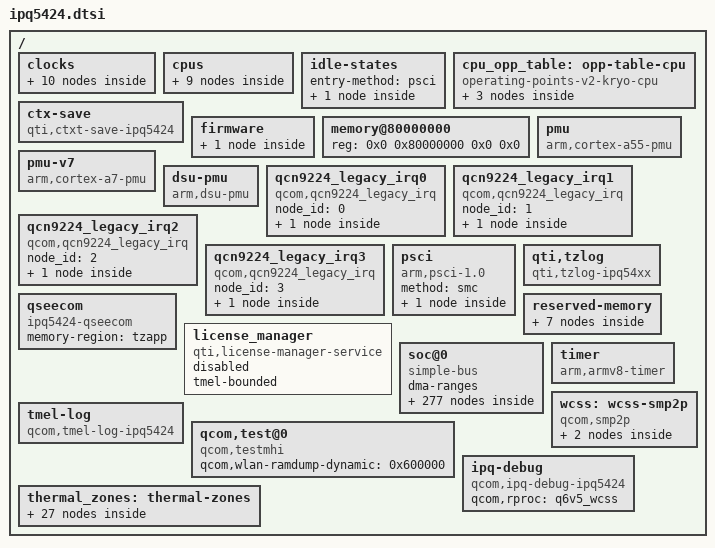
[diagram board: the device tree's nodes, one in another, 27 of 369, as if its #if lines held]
// SPDX-License-Identifier: (GPL-2.0+ OR BSD-3-Clause)
/*
 * IPQ5424 device tree source
 *
 * Copyright (c) 2020-2021 The Linux Foundation. All rights reserved.
 * Copyright (c) 2022-2024 Qualcomm Innovation Center, Inc. All rights reserved.
 */

#include <dt-bindings/interrupt-controller/arm-gic.h>
#include <dt-bindings/clock/qcom,apss-ipq.h>
#include <dt-bindings/clock/qcom,ipq5424-gcc.h>
#include <dt-bindings/reset/qcom,ipq5424-gcc.h>
#include <dt-bindings/gpio/gpio.h>
#include <dt-bindings/clock/qcom,ipq5424-nsscc.h>
#include <dt-bindings/reset/qcom,ipq5424-nsscc.h>

/ {
#ifdef __IPQ_MEM_PROFILE_256_MB__
	MP_256;
#elif __IPQ_MEM_PROFILE_512_MB__
	MP_512;
#endif
	#address-cells = <2>;
	#size-cells = <2>;
	interrupt-parent = <&intc>;

	clocks {
		pcie30_phy0_pipe_clk: pcie30_phy0_pipe_clk {
			compatible = "fixed-clock";
			clock-frequency = <250000000>;
			#clock-cells = <0>;
		};

		pcie30_phy1_pipe_clk: pcie30_phy1_pipe_clk {
			compatible = "fixed-clock";
			clock-frequency = <250000000>;
			#clock-cells = <0>;
		};

		pcie30_phy2_pipe_clk: pcie30_phy2_pipe_clk {
			compatible = "fixed-clock";
			clock-frequency = <250000000>;
			#clock-cells = <0>;
		};

		pcie30_phy3_pipe_clk: pcie30_phy3_pipe_clk {
			compatible = "fixed-clock";
			clock-frequency = <250000000>;
			#clock-cells = <0>;
		};

		sleep_clk: sleep-clk {
			compatible = "fixed-clock";
			#clock-cells = <0>;
		};

		usb_pcie_wrapper_pipe_clk: usb-pcie-wrapper-pipe-clk {
			compatible = "fixed-clock";
			clock-frequency = <125000000>;
			#clock-cells = <0>;
		};

		xo: xo {
			compatible = "fixed-clock";
			#clock-cells = <0>;
		};

		cmn_pll_nss_clk_375m: cmn-pll-nss-clk-375m {
			compatible = "fixed-clock";
			clock-frequency = <375000000>;
			#clock-cells = <0>;
		};

		cmn_pll_nss_clk_300m: cmn-pll-nss-clk-300m {
			compatible = "fixed-clock";
			clock-frequency = <300000000>;
			#clock-cells = <0>;
		};

		gcc_gpll0_out_aux: gcc-gpll0-out-aux {
			compatible = "fixed-clock";
			clock-frequency = <800000000>;
			#clock-cells = <0>;
		};
	};

	cpus: cpus {
		#address-cells = <1>;
		#size-cells = <0>;

		CPU0: cpu@0 {
			device_type = "cpu";
			compatible = "arm,cortex-a55";
			reg = <0x0>;
			enable-method = "psci";
			next-level-cache = <&L2_0>;
			cpu-idle-states = <&LITTLE_CPU_OFF>;
			clocks = <&apss_clk APSS_SILVER_CORE_CLK>;
			clock-names = "cpu";
			operating-points-v2 = <&cpu_opp_table>;
			#cooling-cells = <2>;
			L2_0: l2-cache {
				compatible = "cache";
				cache-level = <2>;
				cache-unified;
				next-level-cache = <&L3_0>;
				L3_0: l3-cache {
					compatible = "cache";
					cache-level = <3>;
					cache-unified;
				};
			};
		};

		CPU1: cpu@100 {
			device_type = "cpu";
			compatible = "arm,cortex-a55";
			enable-method = "psci";
			reg = <0x100>;
			next-level-cache = <&L2_100>;
			cpu-idle-states = <&LITTLE_CPU_OFF>;
			clocks = <&apss_clk APSS_SILVER_CORE_CLK>;
			clock-names = "cpu";
			operating-points-v2 = <&cpu_opp_table>;
			#cooling-cells = <2>;
			L2_100: l2-cache {
				compatible = "cache";
				cache-level = <2>;
				cache-unified;
				next-level-cache = <&L3_0>;
			};
		};

		CPU2: cpu@200 {
			device_type = "cpu";
			compatible = "arm,cortex-a55";
			enable-method = "psci";
			reg = <0x200>;
			next-level-cache = <&L2_200>;
			cpu-idle-states = <&LITTLE_CPU_OFF>;
			clocks = <&apss_clk APSS_SILVER_CORE_CLK>;
			clock-names = "cpu";
			operating-points-v2 = <&cpu_opp_table>;
			#cooling-cells = <2>;
			L2_200: l2-cache {
				compatible = "cache";
				cache-level = <2>;
				cache-unified;
				next-level-cache = <&L3_0>;
			};
		};

		CPU3: cpu@300 {
			device_type = "cpu";
			compatible = "arm,cortex-a55";
			enable-method = "psci";
			reg = <0x300>;
			next-level-cache = <&L2_300>;
			cpu-idle-states = <&LITTLE_CPU_OFF>;
			clocks = <&apss_clk APSS_SILVER_CORE_CLK>;
			clock-names = "cpu";
			operating-points-v2 = <&cpu_opp_table>;
			#cooling-cells = <2>;
			L2_300: l2-cache {
				compatible = "cache";
				cache-level = <2>;
				cache-unified;
				next-level-cache = <&L3_0>;
			};
		};
	};

	idle-states {
		entry-method = "psci";

		LITTLE_CPU_OFF: silver-c3 {  /* C3 */
			compatible = "arm,idle-state";
			idle-state-name = "pc";
			entry-latency-us = <549>;
			exit-latency-us = <901>;
			min-residency-us = <1774>;
			arm,psci-suspend-param = <0x40000003>;
			local-timer-stop;
		};
	};

	cpu_opp_table: opp-table-cpu {
		compatible = "operating-points-v2-kryo-cpu";
		opp-shared;
		nvmem-cells = <&apss_cpu_freq>;
		nvmem-cell-names = "cpu_freq";

		/* Listed all supported CPU frequencies and opp-supported-hw
		 * values to select CPU frequencies based on the PLL LValue.
		 * ------------------------------------------------------------
		 * Frequency     1.4GHz	   1.8GHz(no limit)	opp-supported-hw
		 * ------------------------------------------------------------
		 * 816000000	   1	      1			0x3
		 * 1416000000      1	      1			0x3
		 * 1800000000      0	      1			0x1
		 * -----------------------------------------------------------*/

		opp-816000000 {
			opp-hz = /bits/ 64 <816000000>;
			opp-supported-hw = <0x3>;
			opp-microvolt = <850000>;
			clock-latency-ns = <200000>;
		};

		opp-1416000000 {
			opp-hz = /bits/ 64 <1416000000>;
			opp-supported-hw = <0x3>;
			opp-microvolt = <850000>;
			clock-latency-ns = <200000>;
		};

		opp-1800000000 {
			opp-hz = /bits/ 64 <1800000000>;
			opp-supported-hw = <0x1>;
			opp-microvolt = <1000000>;
			clock-latency-ns = <200000>;
		};
	};

	ctx-save {
		compatible = "qti,ctxt-save-ipq5424";
		memory-region = <&minidump_mem>;
		qcom,imem = <&imem>;
		minidump-level = <2>;
	};

	firmware {
		scm {
			compatible = "qcom,scm-ipq5424", "qcom,scm";
			qcom,dload-mode = <&tcsr 0x25100>;
			qcom,tcsr-boot-info = <&tcsr 0x25158>;
		};
	};

	memory@80000000 {
		device_type = "memory";
		/* We expect the bootloader to fill in the size */
		reg = <0x0 0x80000000 0x0 0x0>;
	};

	pmu {
		compatible = "arm,cortex-a55-pmu";
		interrupts = <GIC_PPI 7 (GIC_CPU_MASK_SIMPLE(4) | IRQ_TYPE_LEVEL_HIGH)>;
	};

	pmu-v7 {
		compatible = "arm,cortex-a7-pmu";
		interrupts = <GIC_PPI 7 (GIC_CPU_MASK_SIMPLE(4) | IRQ_TYPE_LEVEL_HIGH)>;
	};

	dsu-pmu {
                compatible = "arm,dsu-pmu";
                interrupts = <GIC_SPI 50 IRQ_TYPE_EDGE_RISING 0>;
                cpus = <&CPU0>, <&CPU1>, <&CPU2>, <&CPU3>;
                status = "ok";
        };

        qcn9224_legacy_irq0: qcn9224_legacy_irq0 {
		compatible = "qcom,qcn9224_legacy_irq";
		node_id = <0>;
		status = "okay";

		qcn9224_in0: legacy_interrupt {
			interrupt-controller;
			#interrupt-cells = <2>;
		};
	};

	qcn9224_legacy_irq1: qcn9224_legacy_irq1 {
		compatible = "qcom,qcn9224_legacy_irq";
		node_id = <1>;
		status = "okay";

		qcn9224_in1: legacy_interrupt {
			interrupt-controller;
			#interrupt-cells = <2>;
		};
	};

	qcn9224_legacy_irq2: qcn9224_legacy_irq2 {
		compatible = "qcom,qcn9224_legacy_irq";
		node_id = <2>;
		status = "okay";

		qcn9224_in2: legacy_interrupt {
			interrupt-controller;
			#interrupt-cells = <2>;
		};
	};

	qcn9224_legacy_irq3: qcn9224_legacy_irq3 {
		compatible = "qcom,qcn9224_legacy_irq";
		node_id = <3>;
		status = "okay";

		qcn9224_in3: legacy_interrupt {
			interrupt-controller;
			#interrupt-cells = <2>;
		};
	};

	psci {
		compatible = "arm,psci-1.0";
		method = "smc";
		reset-types {
			mode-edl = <0 0x1>;
		};
	};

	qti,tzlog {
		compatible = "qti,tzlog-ipq54xx";
		interrupts = <GIC_SPI 56 IRQ_TYPE_EDGE_RISING>;
		qti,tz-diag-buf-size = <0x3000>;
		qti,tz-ring-off = <7>;
		qti,tz-log-pos-info-off = <822>;
	};

	qseecom: qseecom {
		compatible = "ipq5424-qseecom";
#if !defined(__IPQ_MEM_PROFILE_256_MB__)
		memory-region = <&tzapp>;
#endif
	};

	reserved-memory {
		#address-cells = <2>;
		#size-cells = <2>;
		ranges;

#if !defined(__IPQ_MEM_PROFILE_256_MB__)
		tzapp: tzapp@0x89900000 {
		#if !defined(__IPQ_MEM_PROFILE_512_MB__)
			reg = <0x0 0x89900000 0x0 0x600000>;
		#endif
			no-map;
		};

		bootloader@0x8a200000 {
			reg = <0x0 0x8a200000 0x0 0x400000>;
			no-map;
		};

#else
		secure_upgrade: secure_upgrade@0 {
			reg = <0x0 0x8a300000 0x0 0x500000>;
			no-map;
			status = "disabled";
		};
#endif
		tz@0x8a600000 {
			reg = <0x0 0x8a600000 0x0 0x200000>;
			no-map;
#if defined(__IPQ_MEM_PROFILE_256_MB__)
			status = "disabled";
#endif
		};

		smem@8a800000 {
			compatible = "qcom,smem";
			reg = <0x0 0x8a800000 0x0 0x32000>;
			no-map;

			hwlocks = <&tcsr_mutex 3>;
		};

		atf@8a832000 {
			reg = <0x0 0x8a832000 0x0 0x80000>;
			no-map;
			status = "disabled";
		};

		tmc_etr_region: tmc_etr_dump@0 {
			no-map;
			status = "disabled";
		};

		minidump_mem: minidump_mem@0 {
			no-map;
		};
	};

	license_manager: license_manager {
		compatible = "qti,license-manager-service";
		tmel-bounded;
		status = "disabled";
	};

	soc@0 {
		compatible = "simple-bus";
		#address-cells = <1>;
		#size-cells = <1>;
		ranges = <0 0 0 0xffffffff>;
		dma-ranges;

		qfprom {
			compatible = "qcom,qfprom-ipq5424-sec";
			scm-cmd-id = <0x1f>;
			version-commit-enable = <0x1>;
			reg = <0xA0058 0x4>;
		};

		tsens: thermal-sensor@4a9000 {
			compatible = "qcom,ipq5424-tsens";
			reg = <0x4a9000 0x1000>,
			      <0x4a8000 0x1000>;
			nvmem-cells = <&tsens_mode>, <&tsens_base0>, <&tsens_base1>,
				      <&s9>, <&s10>, <&s11>, <&s12>, <&s13>, <&s14>,
				      <&s15>;
			nvmem-cell-names = "mode", "base0", "base1", "s9",
					   "s10", "s11", "s12", "s13",
					   "s14", "s15";
			interrupts = <GIC_SPI 105 IRQ_TYPE_EDGE_RISING>;
			interrupt-names = "combined";
			#thermal-sensor-cells = <1>;
		};

		eud {
			compatible = "qcom,sc7280-eud","qcom,eud";
			reg = <0x78000 0x2000>,
			      <0x7A000 0x1000>;
			interrupts = <GIC_SPI 415 IRQ_TYPE_LEVEL_HIGH>;
			clocks = <&gcc GCC_USB0_PHY_CFG_AHB_CLK>;
			clock-names = "eud_ahb2phy_clk";
			status = "disabled";
		};

		rng: rng@4c3000 {
			compatible = "qcom,trng";
			reg = <0x004c3000 0x1000>;
			clocks = <&gcc GCC_PRNG_AHB_CLK>;
			clock-names = "core";
		};

		system-cache-controller@800000 {
			compatible = "qcom,ipq5424-llcc";
			reg = <0x00800000 0x200000>, <0x00800000 0x200000>;
			reg-names = "llcc_base", "llcc_broadcast_base";
			interrupts = <GIC_SPI 68 IRQ_TYPE_LEVEL_HIGH>;
			status = "disabled";

			llcc-perfmon {
				compatible = "qcom,llcc-perfmon";
			};
		};

		tlmm: pinctrl@1000000 {
			compatible = "qcom,ipq5424-tlmm";
			reg = <0x01000000 0x300000>;
			interrupts = <GIC_SPI 84 IRQ_TYPE_LEVEL_HIGH>;
			gpio-controller;
			#gpio-cells = <2>;
			gpio-ranges = <&tlmm 0 0 50>;
			interrupt-controller;
			#interrupt-cells = <2>;

			qup_uart0_default: qup-uart0-default-state {
				qup_uart0_tx: tx-pins {
					pins = "gpio13";
					function = "uart0_tx";
					drive-strength = <8>;
					bias-pull-down;
				};

				qup_uart0_rx: rx-pins {
					pins = "gpio12";
					function = "uart0_rx";
					drive-strength = <8>;
					bias-pull-down;
				};

				qup_uart0_rfr: rfr-pins {
					pins = "gpio10";
					function = "uart0_rfr";
					drive-strength = <8>;
					bias-pull-down;
				};

				qup_uart0_cts: cts-pins {
					pins = "gpio11";
					function = "uart0_cts";
					drive-strength = <8>;
					bias-pull-down;
				};
			};
		};

		pcie0_phy: phy@84000 {
			compatible = "qcom,ipq5424-qmp-gen3x1-pcie-phy",
				     "qcom,ipq9574-qmp-gen3x1-pcie-phy";
			reg = <0x00084000 0x1bc>; /* Serdes PLL */
			#address-cells = <1>;
			#size-cells = <1>;
			ranges;

			clocks = <&gcc GCC_PCIE0_AUX_CLK>,
				 <&gcc GCC_PCIE0_AHB_CLK>,
				 <&gcc GCC_ANOC_PCIE0_1LANE_M_CLK>,
				 <&gcc GCC_CNOC_PCIE0_1LANE_S_CLK>;
			clock-names = "aux", "cfg_ahb", "anoc_lane", "snoc_lane";

			assigned-clocks = <&gcc GCC_PCIE0_AUX_CLK>,
					  <&gcc GCC_PCIE0_AHB_CLK>,
					  <&gcc GCC_ANOC_PCIE0_1LANE_M_CLK>,
					  <&gcc GCC_CNOC_PCIE0_1LANE_S_CLK>;
			assigned-clock-rates = <20000000>,
					       <100000000>,
					       <240000000>,
					       <240000000>;

			resets = <&gcc GCC_PCIE0_PHY_BCR>,
				 <&gcc GCC_PCIE0PHY_PHY_BCR>;
			reset-names = "phy", "common";

			status = "disabled";

			pcie0_lanes: phy@84200 {
				reg = <0x00084200 0x16c>, /* Serdes Tx0 */
				      <0x00084400 0x200>, /* Serdes Rx0 */
				      <0x00084800 0x1f0>, /* PCS: Lane0, COM, PCIE */
				      <0x00084c00 0x0f4>; /* pcs_misc */

				#phy-cells = <0>;

				clocks = <&gcc GCC_PCIE0_PIPE_CLK>;
				clock-names = "pipe0";
				clock-output-names = "gcc_pcie0_pipe_clk_src";
				#clock-cells = <0>;
			};
		};

		pcie1_phy: phy@8c000 {
			compatible = "qcom,ipq5424-qmp-gen3x1-pcie-phy",
				     "qcom,ipq9574-qmp-gen3x1-pcie-phy";
			reg = <0x0008c000 0x1bc>; /* Serdes PLL */
			#address-cells = <1>;
			#size-cells = <1>;
			ranges;

			clocks = <&gcc GCC_PCIE1_AUX_CLK>,
				 <&gcc GCC_PCIE1_AHB_CLK>,
				 <&gcc GCC_ANOC_PCIE1_1LANE_M_CLK>,
				 <&gcc GCC_CNOC_PCIE1_1LANE_S_CLK>;
			clock-names = "aux", "cfg_ahb", "anoc_lane", "snoc_lane";

			assigned-clocks = <&gcc GCC_PCIE1_AUX_CLK>,
					  <&gcc GCC_PCIE1_AHB_CLK>,
					  <&gcc GCC_ANOC_PCIE1_1LANE_M_CLK>,
					  <&gcc GCC_CNOC_PCIE1_1LANE_S_CLK>;
			assigned-clock-rates = <20000000>,
					       <100000000>,
					       <240000000>,
					       <240000000>;

			resets = <&gcc GCC_PCIE1_PHY_BCR>,
				 <&gcc GCC_PCIE1PHY_PHY_BCR>;
			reset-names = "phy", "common";

			status = "disabled";

			pcie1_lanes: phy@8c200 {
				reg = <0x0008c200 0x16c>, /* Serdes Tx0 */
				      <0x0008c400 0x200>, /* Serdes Rx0 */
				      <0x0008c800 0x1f0>, /* PCS: Lane0, COM, PCIE */
				      <0x0008cc00 0x0f4>; /* pcs_misc */

				#phy-cells = <0>;

				clocks = <&gcc GCC_PCIE1_PIPE_CLK>;
				clock-names = "pipe0";
				clock-output-names = "gcc_pcie1_pipe_clk_src";
				#clock-cells = <0>;
			};
		};

		pcie2_phy: phy@f4000 {
			compatible = "qcom,ipq5424-qmp-gen3x2-pcie-phy",
				     "qcom,ipq9574-qmp-gen3x2-pcie-phy";
			reg = <0x000f4000 0x1bc>; /* Serdes PLL */
			#address-cells = <1>;
			#size-cells = <1>;
			ranges;

			clocks = <&gcc GCC_PCIE2_AUX_CLK>,
				 <&gcc GCC_PCIE2_AHB_CLK>,
				 <&gcc GCC_ANOC_PCIE2_2LANE_M_CLK>,
				 <&gcc GCC_CNOC_PCIE2_2LANE_S_CLK>;
			clock-names = "aux", "cfg_ahb", "anoc_lane", "snoc_lane";

			assigned-clocks = <&gcc GCC_PCIE2_AUX_CLK>,
					  <&gcc GCC_PCIE2_AHB_CLK>,
					  <&gcc GCC_ANOC_PCIE2_2LANE_M_CLK>,
					  <&gcc GCC_CNOC_PCIE2_2LANE_S_CLK>;
			assigned-clock-rates = <20000000>,
					       <100000000>,
					       <266666666>,
					       <240000000>;

			resets = <&gcc GCC_PCIE2_PHY_BCR>,
				 <&gcc GCC_PCIE2PHY_PHY_BCR>;
			reset-names = "phy", "common";

			status = "disabled";

			pcie2_lanes: phy@f4200 {
				reg = <0x000f4200 0x16c>, /* Serdes Tx0 */
				      <0x000f4400 0x200>, /* Serdes Rx0 */
				      <0x000f5000 0x1f0>, /* PCS: Lane0, COM, PCIE */
				      <0x000f4600 0x16c>, /* Serdes Tx1 */
				      <0x000f4800 0x200>, /* Serdes Rx1 */
				      <0x000f5400 0x0f8>; /* pcs_misc */

				#phy-cells = <0>;

				clocks = <&gcc GCC_PCIE2_PIPE_CLK>;
				clock-names = "pipe0";
				clock-output-names = "gcc_pcie2_pipe_clk_src";
				#clock-cells = <0>;
			};
		};

		pcie3_phy: phy@fc000 {
			compatible = "qcom,ipq5424-qmp-gen3x2-pcie-phy",
				     "qcom,ipq9574-qmp-gen3x2-pcie-phy";
			reg = <0x000fc000 0x1bc>; /* Serdes PLL */
			#address-cells = <1>;
			#size-cells = <1>;
			ranges;

			clocks = <&gcc GCC_PCIE3_AUX_CLK>,
				 <&gcc GCC_PCIE3_AHB_CLK>,
				 <&gcc GCC_ANOC_PCIE3_2LANE_M_CLK>,
				 <&gcc GCC_CNOC_PCIE3_2LANE_S_CLK>;
			clock-names = "aux", "cfg_ahb", "anoc_lane", "snoc_lane";

			assigned-clocks = <&gcc GCC_PCIE3_AUX_CLK>,
					  <&gcc GCC_PCIE3_AHB_CLK>,
					  <&gcc GCC_ANOC_PCIE3_2LANE_M_CLK>,
					  <&gcc GCC_CNOC_PCIE3_2LANE_S_CLK>;
			assigned-clock-rates = <20000000>,
					       <100000000>,
					       <266666666>,
					       <240000000>;

			resets = <&gcc GCC_PCIE3_PHY_BCR>,
				 <&gcc GCC_PCIE3PHY_PHY_BCR>;
			reset-names = "phy", "common";

			status = "disabled";

			pcie3_lanes: phy@fc200 {
				reg = <0x000fc200 0x16c>, /* Serdes Tx0 */
				      <0x000fc400 0x200>, /* Serdes Rx0 */
				      <0x000fd000 0x1f0>, /* PCS: Lane0, COM, PCIE */
				      <0x000fc600 0x16c>, /* Serdes Tx1 */
				      <0x000fc800 0x200>, /* Serdes Rx1 */
				      <0x000fd400 0x0f8>; /* pcs_misc */

				#phy-cells = <0>;

				clocks = <&gcc GCC_PCIE3_PIPE_CLK>;
				clock-names = "pipe0";
				clock-output-names = "gcc_pcie3_pipe_clk_src";
				#clock-cells = <0>;
			};
		};

		efuse@a4000 {
			compatible = "qcom,qfprom";
			reg = <0xA4000 0x741>;
			#address-cells = <1>;
			#size-cells = <1>;

			s9: s9@3dc {
				reg = <0x3dc 0x1>;
				bits = <4 4>;
			};

			s10: s10@3dd {
				reg = <0x3dd 0x1>;
				bits = <0 4>;
			};

			s11: s11@3dd {
				reg = <0x3dd 0x1>;
				bits = <4 4>;
			};

			s12: s12@3de {
				reg = <0x3de 0x1>;
				bits = <0 4>;
			};

			s13: s13@3de {
				reg = <0x3de 0x1>;
				bits = <4 4>;
			};

			s14: s14@3e5 {
				reg = <0x3e5 0x2>;
				bits = <7 4>;
			};

			s15: s15@3e6 {
				reg = <0x3e6 0x1>;
				bits = <3 4>;
			};

			tsens_mode: mode@419 {
				reg = <0x419 0x1>;
				bits = <0 3>;
			};

			tsens_base0: base0@419 {
				reg = <0x419 0x2>;
				bits = <3 10>;
			};

			tsens_base1: base1@41a {
				reg = <0x41a 0x2>;
				bits = <5 10>;
			};
		};

		softsku@a6000 {
			compatible = "qcom,qfprom";
			reg = <0xA6000 0x1000>;
			#address-cells = <1>;
			#size-cells = <1>;

			apss_cpu_freq: apss_cpu_freq@234 {
				reg = <0x234 0x1>;
				bits = <0 8>;
			};

			ddr_space_limit: ddr_space_limit@23c {
				reg = <0x23c 0x1>;
				bits = <0 1>;
			};

			pcie0_disable: pcie0_disable@244 {
				reg = <0x244 0x1>;
				bits = <0 1>;
			};

			pcie1_disable: pcie1_disable@24c {
				reg = <0x24c 0x1>;
				bits = <0 1>;
			};

			pcie2_disable: pcie2_disable@254 {
				reg = <0x254 0x1>;
				bits = <0 1>;
			};

			pcie3_disable: pcie3_disable@25c {
				reg = <0x25c 0x1>;
				bits = <0 1>;
			};

			uniphy0_disable: uniphy0_disable@264 {
				reg = <0x264 0x1>;
				bits = <0 1>;
			};

			uniphy1_disable: uniphy1_disable@26c {
				reg = <0x26c 0x1>;
				bits = <0 1>;
			};

			uniphy2_disable: uniphy2_disable@274 {
				reg = <0x274 0x1>;
				bits = <0 1>;
			};

			audio_disable: audio_disable@27c {
				reg = <0x27c 0x1>;
				bits = <0 1>;
			};

			nss_disable: nss_disable@284 {
				reg = <0x284 0x1>;
				bits = <0 1>;
			};

			usb_disable: usb_disable@28c {
				reg = <0x28c 0x1>;
				bits = <0 1>;
			};
		};

		gcc: clock-controller@1800000 {
			compatible = "qcom,ipq5424-gcc";
			reg = <0x01800000 0x40000>;
			clocks = <&xo>,
				 <&sleep_clk>,
				 <&pcie30_phy0_pipe_clk>,
				 <&pcie30_phy1_pipe_clk>,
				 <&pcie30_phy2_pipe_clk>,
				 <&pcie30_phy3_pipe_clk>,
				 <&usb_pcie_wrapper_pipe_clk>,
				 <&cmn_pll_nss_clk_375m>;
			#clock-cells = <1>;
			#reset-cells = <1>;
			#power-domain-cells = <1>;
                };

		nsscc: nsscc@39b00000{
			compatible = "qcom,ipq54xx-nsscc";
			reg = <0x39b00000 0x80000>;
			clocks = <&xo>,
				<&cmn_pll_nss_clk_375m>,
				<&cmn_pll_nss_clk_300m>,
				<&gcc_gpll0_out_aux>;
			clock-names = "xo",
					"cmn_pll_nss_clk_375m",
					"cmn_pll_nss_clk_300m",
					"gcc_gpll0_out_aux";
			#clock-cells = <0x1>;
			#reset-cells = <0x1>;
		};

		tcsr_mutex: hwlock@1905000 {
			compatible = "qcom,tcsr-mutex";
			reg = <0x1905000 0x20000>;
			#hwlock-cells = <1>;
		};

		tcsr: syscon@1937000 {
			compatible = "qcom,tcsr-ipq5424", "syscon", "simple-mfd";
			reg = <0x01937000 0x2a000>;
			#address-cells = <1>;
			#size-cells = <1>;
			ranges = <0x0 0x01937000 0x2a000>;

			 pwm: pwm@a010 {
				compatible = "qcom,ipq9574-pwm";
				reg = <0xa010 0x20>;
				clocks = <&gcc GCC_ADSS_PWM_CLK>;
				assigned-clocks = <&gcc GCC_ADSS_PWM_CLK>;
				assigned-clock-rates = <100000000>;
				#pwm-cells = <2>;
				status = "disabled";
			};
		};

		qupv3: geniqup@1ac0000 {
			compatible = "qcom,geni-se-qup";
			reg = <0x01ac0000 0x2000>;
			clocks = <&gcc GCC_QUPV3_AHB_MST_CLK>,
				 <&gcc GCC_QUPV3_AHB_SLV_CLK>;
			clock-names = "m-ahb", "s-ahb";
			ranges;
			#address-cells = <1>;
			#size-cells = <1>;

			status = "disabled";

			uart0: serial@1a80000 {
				compatible = "qcom,geni-uart";
				reg = <0x01a80000 0x4000>;
				clocks = <&gcc GCC_QUPV3_UART0_CLK>;
				clock-names = "se";
				interrupts = <GIC_SPI 339 IRQ_TYPE_LEVEL_HIGH>;
				status = "disabled";
			};

			uart1: serial@1a84000 {
				compatible = "qcom,geni-debug-uart";
				reg = <0x01a84000 0x4000>;
				clocks = <&gcc GCC_QUPV3_UART1_CLK>;
				clock-names = "se";
				interrupts = <GIC_SPI 340 IRQ_TYPE_LEVEL_HIGH>;
				status = "disabled";
			};

			i2c0: i2c@1a88000 {
				compatible = "qcom,geni-i2c";
				reg = <0x1a88000 0x4000>;
				clocks = <&gcc GCC_QUPV3_I2C0_CLK>;
				clock-names = "se";
				clock-frequency = <400000>;
				interrupts = <GIC_SPI 341 IRQ_TYPE_LEVEL_HIGH>;
				assigned-clocks = <&gcc GCC_QUPV3_I2C0_CLK>;
				assigned-clock-rates = <64000000>;
				status = "disabled";
			};

			i2c1: i2c@1a8c000 {
				compatible = "qcom,geni-i2c";
				reg = <0x1a8c000 0x4000>;
				clocks = <&gcc GCC_QUPV3_I2C1_CLK>;
				clock-names = "se";
				clock-frequency = <400000>;
				interrupts = <GIC_SPI 342 IRQ_TYPE_LEVEL_HIGH>;
				assigned-clocks = <&gcc GCC_QUPV3_I2C1_CLK>;
				assigned-clock-rates = <64000000>;
				status = "disabled";
			};

			spi0: spi@1a90000 {
				compatible = "qcom,geni-spi";
				reg = <0x1a90000 0x4000>;
				clocks = <&gcc GCC_QUPV3_SPI0_CLK>;
				clock-names = "se";
				interrupts = <GIC_SPI 343 IRQ_TYPE_LEVEL_HIGH>;
				assigned-clocks = <&gcc GCC_QUPV3_SPI0_CLK>;
				assigned-clock-rates = <50000000>;
				status = "disabled";
			};

			spi1: spi@1a94000 {
				compatible = "qcom,geni-spi";
				reg = <0x1a94000 0x4000>;
				clocks = <&gcc GCC_QUPV3_SPI1_CLK>;
				clock-names = "se";
				interrupts = <GIC_SPI 344 IRQ_TYPE_LEVEL_HIGH>;
				assigned-clocks = <&gcc GCC_QUPV3_SPI1_CLK>;
				assigned-clock-rates = <50000000>;
				status = "disabled";
			};
		};

		apss_clk: apss-clock@fa80000 {
			compatible = "qcom,apss-ipq5424-clk";
			reg = <0x0fa80000 0x20000>;
			clocks = <&xo>, <&gcc GPLL0>;
			clock-names = "xo", "gpll0";
			#clock-cells = <1>;
                };

		lpass: lpass@0xA000000{
			compatible = "qca,lpass-ipq5424";
			reg =  <0xA000000 0x3BFFFF>;
			clocks = <&gcc GCC_LPASS_SWAY_CLK>,
			<&gcc GCC_LPASS_CORE_AXIM_CLK>,
			<&gcc GCC_SNOC_LPASS_CLK>,
			<&gcc GCC_CNOC_LPASS_CFG_CLK>;
			clock-names = "sway", "axim", "snoc_cfg", "pcnoc";
			resets = <&gcc GCC_LPASS_BCR>;
			reset-names = "lpass";
			nvmem-cells = <&audio_disable>;
			#address-cells = <1>;
			#size-cells = <1>;
			ranges;
			status = "disabled";

			pcm: pcm@0xA3C0000{
				compatible = "qca,ipq5424-lpass-pcm";
				reg =  <0xA3C0000 0x23014>;
				status = "disabled";

				pcm0: pcm0@0 {
					interrupts = <0 159 IRQ_TYPE_LEVEL_HIGH>;
					interrupt-names = "out0";
					capture_memory = "lpm";
					playback_memory = "lpm";
					voice_loopback = <0>;
					slave = <0>;
					status = "disabled";
				};

				pcm1: pcm1@1 {
					interrupts = <0 160 IRQ_TYPE_LEVEL_HIGH>;
					interrupt-names = "out1";
					capture_memory = "lpm";
					playback_memory = "lpm";
					voice_loopback = <0>;
					slave = <0>;
					status = "disabled";
				};
			};
		};

		pcm_lb: pcm_lb@0 {
			compatible = "qca,ipq5424-pcm-lb";
			status = "disabled";
		};

		q6v5_wcss: remoteproc@d100000 {
			compatible = "qcom,ipq5424-q6v5-wcss-sec";
			#address-cells = <1>;
			#size-cells = <1>;
			ranges;
#ifdef __QCOM_NON_SECURE_PIL__
			reg = <0xd100000 0x4040>;
			reg-names = "qdsp6";
			resets = <&gcc GCC_WCSS_Q6_BCR>,
				 <&gcc GCC_WAPSS_BCR>;
			reset-names = "wcss_q6_reset",
				      "wapss_reset";
			clocks = <&gcc GCC_Q6_TSCTR_1TO2_CLK>,
				 <&gcc GCC_Q6SS_TRIG_CLK>,
				 <&gcc GCC_Q6_AHB_S_CLK>,
				 <&gcc GCC_Q6_AHB_CLK>,
				 <&gcc GCC_Q6SS_ATBM_CLK>,
				 <&gcc GCC_Q6_AXIM_CLK>,
				 <&gcc GCC_Q6SS_BOOT_CLK>,
				 <&gcc GCC_Q6SS_PCLKDBG_CLK>,
				 <&gcc GCC_WCSS_ECAHB_CLK>,
				 <&gcc GCC_CNOC_WCSS_AHB_CLK>;

			clock-names = "q6_tsctr_1to2",
				      "q6ss_trig",
				      "q6_ahb_s",
				      "q6_ahb",
				      "q6ss_atbm",
				      "q6_axim",
				      "q6ss_boot",
				      "q6ss_pclkdbg",
				      "wcss_ecahb",
				      "cnoc_wcss_ahb";
			qcom,q6-tcsr-regs = <&tcsr 0x26000 0x1B000>;
#endif
			firmware = "IPQ5424/q6_fw0.mdt";
			interrupts-extended = <&intc GIC_SPI 508 IRQ_TYPE_EDGE_RISING>,
					      <&wcss_smp2p_in 0 0>,
					      <&wcss_smp2p_in 1 0>,
					      <&wcss_smp2p_in 2 0>,
					      <&wcss_smp2p_in 3 0>;
			interrupt-names = "wdog",
					  "fatal",
					  "ready",
					  "handover",
					  "stop-ack";
			qcom,smem-states = <&wcss_smp2p_out 0>,
					   <&wcss_smp2p_out 1>;
			qcom,smem-state-names = "shutdown",
						"stop";

			memory-region = <&q6_region>,
					<&m3_dump>,
					<&q6_etr_region>,
					<&q6_ipq5424_caldb>,
					<&mlo_global_mem0>;
			qcom,bootargs_smem = <507>;
			qcom,bootargs_version = <2>;
			qcom,userpd-bootargs;
			upd-firmware-names = "IPQ5424/q6_fw1.mdt";
			status = "disabled";

			glink-edge {
				interrupts = <GIC_SPI 500 IRQ_TYPE_EDGE_RISING>;
				label = "rtr";
				qcom,remote-pid = <1>;
				mboxes = <&apcs_glb 8>;
				global_timer = <0x4A5000>;
			};

#ifdef __QCOM_NON_SECURE_PIL__
			q6_wcss_pd1: remoteproc_pd1 {
				compatible = "qcom,ipq5424-wcss-ahb-mpd";
				firmware = "IPQ5424/q6_fw1.mdt";
				m3_firmware = "IPQ5424/iu_fw.mdt";
				interrupts-extended = <&wcss_smp2p_in 8 0>,
						      <&wcss_smp2p_in 9 0>,
						      <&wcss_smp2p_in 12 0>,
						      <&wcss_smp2p_in 11 0>;
				interrupt-names = "fatal",
						  "ready",
						  "spawn-ack",
						  "stop-ack";

				qcom,smem-states = <&wcss_smp2p_out 8>,
						   <&wcss_smp2p_out 9>,
						   <&wcss_smp2p_out 10>;
				qcom,smem-state-names = "shutdown",
							"stop",
							"spawn";
				status = "disabled";
			};
#endif
		};

		userpd_1: userpd1 {
			compatible = "qcom,ipq5424-q6v5-upd";
			memory-region = <&q6_region>;
			qcom,rproc = <&q6v5_wcss>;
			firmware = "IPQ5424/q6_fw1.mdt";
			m3_firmware = "IPQ5424/iu_fw.mdt";
			interrupts-extended = <&wcss_smp2p_in 8 0>,
					      <&wcss_smp2p_in 9 0>,
					      <&wcss_smp2p_in 12 0>,
					      <&wcss_smp2p_in 11 0>;
			interrupt-names = "fatal",
					  "ready",
					  "spawn-ack",
					  "stop-ack";

			qcom,smem-states = <&wcss_smp2p_out 8>,
					   <&wcss_smp2p_out 9>,
					   <&wcss_smp2p_out 10>;
			qcom,smem-state-names = "shutdown",
						"stop",
						"spawn";
			status = "disabled";
		};

		intc: interrupt-controller@f200000 {
			compatible = "arm,gic-v3";
			reg = <0xf200000 0x10000>, /* GICD */
			      <0xf240000 0x80000>; /* GICR * 4 regions */
			#interrupt-cells = <0x3>;
			interrupt-controller;
			#redistributor-regions = <1>;
			redistributor-stride = <0x0 0x20000>;
			interrupts = <GIC_PPI 9 IRQ_TYPE_LEVEL_HIGH>;
			mbi-ranges = <672 128>;
			msi-controller;
		};

		mdio@90000 {
			compatible = "qcom,qca-mdio", "qcom,ipq40xx-mdio";
			reg = <0x90000 0x64>, <0x9B000 0x800>;
			reg-names = "ppe", "cmn_blk";
			#address-cells = <1>;
			#size-cells = <1>;
			clocks = <&gcc GCC_MDIO_AHB_CLK>,
				<&gcc GCC_UNIPHY0_AHB_CLK>,
				<&gcc GCC_UNIPHY0_SYS_CLK>,
				<&gcc GCC_UNIPHY1_AHB_CLK>,
				<&gcc GCC_UNIPHY1_SYS_CLK>,
				<&gcc GCC_UNIPHY2_AHB_CLK>,
				<&gcc GCC_UNIPHY2_SYS_CLK>;
			clock-names = "gcc_mdio_ahb_clk",
				"uniphy0_ahb_clk",
				"uniphy0_sys_clk",
				"uniphy1_ahb_clk",
				"uniphy1_sys_clk",
				"uniphy2_ahb_clk",
				"uniphy2_sys_clk";
			status = "disabled";
		};

		ess-instance {
			compatible = "qcom,ess-instance";
#ifdef __CONFIG_IO_COHERENCY__
			dma-coherent;
#endif
			ess-switch@3a000000 {
				compatible = "qcom,ess-switch-ipq54xx";
#ifdef __CONFIG_IO_COHERENCY__
				dma-coherent;
#endif
				switch_access_mode = "local bus";
				reg = <0x3a000000 0x1000000>;
				clocks = <&gcc GCC_CMN_12GPLL_AHB_CLK>,
					<&gcc GCC_CMN_12GPLL_SYS_CLK>,
					<&gcc GCC_UNIPHY0_AHB_CLK>,
					<&gcc GCC_UNIPHY0_SYS_CLK>,
					<&gcc GCC_UNIPHY1_AHB_CLK>,
					<&gcc GCC_UNIPHY1_SYS_CLK>,
					<&gcc GCC_UNIPHY2_AHB_CLK>,
					<&gcc GCC_UNIPHY2_SYS_CLK>,
					<&gcc GCC_NSSNOC_NSSCC_CLK>,
					<&gcc GCC_NSSCC_CLK>,
					<&gcc GCC_NSSNOC_SNOC_1_CLK>,
					<&gcc GCC_NSSNOC_SNOC_CLK>,
					<&nsscc NSS_CC_PORT1_MAC_CLK>,
					<&nsscc NSS_CC_PORT2_MAC_CLK>,
					<&nsscc NSS_CC_PORT3_MAC_CLK>,
					<&nsscc NSS_CC_PPE_SWITCH_CLK>,
					<&nsscc NSS_CC_PPE_SWITCH_CFG_CLK>,
					<&nsscc NSS_CC_NSSNOC_PPE_CLK>,
					<&nsscc NSS_CC_NSSNOC_PPE_CFG_CLK>,
					<&nsscc NSS_CC_PPE_EDMA_CLK>,
					<&nsscc NSS_CC_PPE_EDMA_CFG_CLK>,
					<&nsscc NSS_CC_PPE_SWITCH_IPE_CLK>,
					<&nsscc NSS_CC_PPE_SWITCH_BTQ_CLK>,
					<&nsscc NSS_CC_PORT1_RX_CLK>,
					<&nsscc NSS_CC_PORT1_TX_CLK>,
					<&nsscc NSS_CC_PORT2_RX_CLK>,
					<&nsscc NSS_CC_PORT2_TX_CLK>,
					<&nsscc NSS_CC_PORT3_RX_CLK>,
					<&nsscc NSS_CC_PORT3_TX_CLK>,
					<&nsscc NSS_CC_UNIPHY_PORT1_RX_CLK>,
					<&nsscc NSS_CC_UNIPHY_PORT1_TX_CLK>,
					<&nsscc NSS_CC_UNIPHY_PORT2_RX_CLK>,
					<&nsscc NSS_CC_UNIPHY_PORT2_TX_CLK>,
					<&nsscc NSS_CC_UNIPHY_PORT3_RX_CLK>,
					<&nsscc NSS_CC_UNIPHY_PORT3_TX_CLK>;
				clock-names = "cmn_ahb_clk",
					"cmn_sys_clk",
					"uniphy0_ahb_clk",
					"uniphy0_sys_clk",
					"uniphy1_ahb_clk",
					"uniphy1_sys_clk",
					"uniphy2_ahb_clk",
					"uniphy2_sys_clk",
					"gcc_nssnoc_nsscc_clk",
					"gcc_nsscc_clk",
					"gcc_nssnoc_snoc_1_clk",
					"gcc_nssnoc_snoc_clk",
					"port1_mac_clk",
					"port2_mac_clk",
					"port3_mac_clk",
					"nss_ppe_clk",
					"nss_ppe_cfg_clk",
					"nssnoc_ppe_clk",
					"nssnoc_ppe_cfg_clk",
					"nss_edma_clk",
					"nss_edma_cfg_clk",
					"nss_ppe_ipe_clk",
					"nss_ppe_btq_clk",
					"nss_port1_rx_clk",
					"nss_port1_tx_clk",
					"nss_port2_rx_clk",
					"nss_port2_tx_clk",
					"nss_port3_rx_clk",
					"nss_port3_tx_clk",
					"uniphy0_port1_rx_clk",
					"uniphy0_port1_tx_clk",
					"uniphy1_port5_rx_clk",
					"uniphy1_port5_tx_clk",
					"uniphy2_port6_rx_clk",
					"uniphy2_port6_tx_clk";
				resets = <&nsscc NSS_CC_PPE_BCR>,
					<&gcc GCC_UNIPHY0_BCR>,
					<&gcc GCC_UNIPHY1_BCR>,
					<&gcc GCC_UNIPHY2_BCR>,
					<&gcc GCC_UNIPHY0_AHB_ARES>,
					<&gcc GCC_UNIPHY1_AHB_ARES>,
					<&gcc GCC_UNIPHY2_AHB_ARES>,
					<&gcc GCC_UNIPHY0_SYS_ARES>,
					<&gcc GCC_UNIPHY1_SYS_ARES>,
					<&gcc GCC_UNIPHY2_SYS_ARES>,
					<&gcc GCC_UNIPHY0_XPCS_ARES>,
					<&gcc GCC_UNIPHY1_XPCS_ARES>,
					<&gcc GCC_UNIPHY2_XPCS_ARES>,
					<&nsscc NSS_CC_UNIPHY_PORT1_RX_CLK_ARES>,
					<&nsscc NSS_CC_UNIPHY_PORT1_TX_CLK_ARES>,
					<&nsscc NSS_CC_UNIPHY_PORT2_RX_CLK_ARES>,
					<&nsscc NSS_CC_UNIPHY_PORT2_TX_CLK_ARES>,
					<&nsscc NSS_CC_UNIPHY_PORT3_RX_CLK_ARES>,
					<&nsscc NSS_CC_UNIPHY_PORT3_TX_CLK_ARES>,
					<&nsscc NSS_CC_PORT1_RX_CLK_ARES>,
					<&nsscc NSS_CC_PORT1_TX_CLK_ARES>,
					<&nsscc NSS_CC_PORT2_RX_CLK_ARES>,
					<&nsscc NSS_CC_PORT2_TX_CLK_ARES>,
					<&nsscc NSS_CC_PORT3_RX_CLK_ARES>,
					<&nsscc NSS_CC_PORT3_TX_CLK_ARES>,
					<&nsscc NSS_CC_PORT1_MAC_CLK_ARES>,
					<&nsscc NSS_CC_PORT2_MAC_CLK_ARES>,
					<&nsscc NSS_CC_PORT3_MAC_CLK_ARES>;
				reset-names = "ppe_rst",
					"uniphy0_soft_rst",
					"uniphy1_soft_rst",
					"uniphy2_soft_rst",
					"uniphy0_ahb_rst",
					"uniphy1_ahb_rst",
					"uniphy2_ahb_rst",
					"uniphy0_sys_rst",
					"uniphy1_sys_rst",
					"uniphy2_sys_rst",
					"uniphy0_xpcs_rst",
					"uniphy1_xpcs_rst",
					"uniphy2_xpcs_rst",
					"uniphy_port1_rx_rst",
					"uniphy_port1_tx_rst",
					"uniphy_port2_rx_rst",
					"uniphy_port2_tx_rst",
					"uniphy_port3_rx_rst",
					"uniphy_port3_tx_rst",
					"nss_port1_rx_rst",
					"nss_port1_tx_rst",
					"nss_port2_rx_rst",
					"nss_port2_tx_rst",
					"nss_port3_rx_rst",
					"nss_port3_tx_rst",
					"nss_port1_mac_rst",
					"nss_port2_mac_rst",
					"nss_port3_mac_rst";

				port_scheduler_resource {
					port@0 {
						port_id = <0>;
						ucast_queue = <0 95>;
						mcast_queue = <256 263>;
						l0sp = <0 0>;
						l0cdrr = <0 7>;
						l0edrr = <0 7>;
						l1cdrr = <0 0>;
						l1edrr = <0 0>;
					};
					port@1 {
						port_id = <1>;
						ucast_queue = <144 159>;
						mcast_queue = <272 275>;
						l0sp = <36 39>;
						l0cdrr = <48 63>;
						l0edrr = <48 63>;
						l1cdrr = <8 11>;
						l1edrr = <8 11>;
					};
					port@2 {
						port_id = <2>;
						ucast_queue = <160 175>;
						mcast_queue = <276 279>;
						l0sp = <40 43>;
						l0cdrr = <64 79>;
						l0edrr = <64 79>;
						l1cdrr = <12 15>;
						l1edrr = <12 15>;
					};
					port@3 {
						port_id = <3>;
						ucast_queue = <176 191>;
						mcast_queue = <280 283>;
						l0sp = <44 47>;
						l0cdrr = <80 95>;
						l0edrr = <80 95>;
						l1cdrr = <16 19>;
						l1edrr = <16 19>;
					};
					reserved {
						ucast_queue = <96 143>;
						mcast_queue = <264 271>;
						l0sp = <1 35>;
						l0cdrr = <8 47>;
						l0edrr = <8 47>;
						l1cdrr = <1 7>;
						l1edrr = <1 7>;
					};
				};
				port_scheduler_config {
					port@0 {
						port_id = <0>;
						l1scheduler {
							group@0 {
								/* L0 SP */
								sp = <0>;
								/* cpri cdrr epri edrr */
								cfg = <0 0 0 0>;
							};
						};
						l0scheduler {
							group@0 {
								/* unicast queue */
								ucast_queue = <0>;
								ucast_loop_pri = <8>;
								/* multicast queue */
								mcast_queue = <256>;
								/* sp cpri cdrr epri edrr */
								cfg = <0 0 0 0 0>;
							};
							group@1 {
								ucast_queue = <8>;
								ucast_loop_pri = <8>;
								mcast_queue = <257>;
								cfg = <0 0 0 0 0>;
							};
							group@2 {
								ucast_queue = <16>;
								ucast_loop_pri = <8>;
								mcast_queue = <258>;
								cfg = <0 0 0 0 0>;
							};
							group@3 {
								ucast_queue = <24>;
								ucast_loop_pri = <8>;
								mcast_queue = <259>;
								cfg = <0 0 0 0 0>;
							};
							group@4 {
								ucast_queue = <32>;
								ucast_loop_pri = <8>;
								mcast_queue = <260>;
								cfg = <0 0 0 0 0>;
							};
							group@5 {
								ucast_queue = <40>;
								ucast_loop_pri = <8>;
								mcast_queue = <261>;
								cfg = <0 0 0 0 0>;
							};
							group@6 {
								ucast_queue = <48>;
								ucast_loop_pri = <8>;
								mcast_queue = <262>;
								cfg = <0 0 0 0 0>;
							};
							group@7 {
								ucast_queue = <56>;
								ucast_loop_pri = <8>;
								mcast_queue = <263>;
								cfg = <0 0 0 0 0>;
							};
							group@8 {
								ucast_queue = <64>;
								ucast_loop_pri = <8>;
								cfg = <0 0 0 0 0>;
							};
							group@9 {
								ucast_queue = <72>;
								ucast_loop_pri = <8>;
								cfg = <0 0 0 0 0>;
							};
							group@a {
								ucast_queue = <80>;
								ucast_loop_pri = <8>;
								cfg = <0 0 0 0 0>;
							};
							group@b {
								ucast_queue = <88>;
								ucast_loop_pri = <8>;
								cfg = <0 0 0 0 0>;
							};
						};
					};
					port@1 {
						port_id = <1>;
						l1scheduler {
							group@0 {
								sp = <36>;
								cfg = <0 8 0 8>;
							};
							group@1 {
								sp = <37>;
								cfg = <0 8 0 8>;
							};
						};
						l0scheduler {
							group@0 {
								ucast_queue = <144>;
								ucast_loop_pri = <16>;
								mcast_queue = <272>;
								mcast_loop_pri = <4>;
								cfg = <36 0 48 0 48>;
							};
						};
					};
					port@2 {
						port_id = <2>;
						l1scheduler {
							group@0 {
								sp = <40>;
								cfg = <0 12 0 12>;
							};
							group@1 {
								sp = <41>;
								cfg = <0 12 0 12>;
							};
						};
						l0scheduler {
							group@0 {
								ucast_queue = <160>;
								ucast_loop_pri = <16>;
								mcast_queue = <276>;
								mcast_loop_pri = <4>;
								cfg = <40 0 64 0 64>;
							};
						};
					};
					port@3 {
						port_id = <3>;
						l1scheduler {
							group@0 {
								sp = <44>;
								cfg = <0 16 0 16>;
							};
							group@1 {
								sp = <45>;
								cfg = <0 16 0 16>;
							};
						};
						l0scheduler {
							group@0 {
								ucast_queue = <176>;
								ucast_loop_pri = <16>;
								mcast_queue = <280>;
								mcast_loop_pri = <4>;
								cfg = <44 0 80 0 80>;
							};
						};
					};
				};
			};
		};

		dcc@60ff000 {
			compatible = "qcom,dcc-v2-ipq5332";
			reg = <0x60ff000 0x1000>,
			      <0x6084000 0x4000>;
			reg-names = "dcc-base", "dcc-ram-base";
			dcc-ram-offset = <0x4000>;
			status = "disabled";
		};

		sdhc: mmc@7804000 {
			compatible = "qcom,ipq5424-sdhci", "qcom,sdhci-msm-v5";
			reg = <0x07804000 0x1000>, <0x07805000 0x1000>,
			      <0x07808000 0x2000>;
			reg-names = "hc", "cqhci", "ice";

			interrupts = <GIC_SPI 116 IRQ_TYPE_LEVEL_HIGH>,
				     <GIC_SPI 119 IRQ_TYPE_LEVEL_HIGH>;
			interrupt-names = "hc_irq", "pwr_irq";

			clocks = <&gcc GCC_SDCC1_AHB_CLK>,
				 <&gcc GCC_SDCC1_APPS_CLK>,
				 <&xo>,
				 <&gcc GCC_SDCC1_ICE_CORE_CLK>;
			clock-names = "iface", "core", "xo", "ice";

			assigned-clocks = <&gcc GCC_SDCC1_ICE_CORE_CLK>;
			assigned-clock-rates = <300000000>;
			pinctrl-0 = <&sdc_default_state>;
			pinctrl-names = "default";
			supports-cqe;

			status = "disabled";
		};

		qpic_bam: dma-controller@7984000 {
			compatible = "qcom,bam-v1.7.0";
			reg = <0x7984000 0x1c000>;
			interrupts = <GIC_SPI 109 IRQ_TYPE_LEVEL_HIGH>;
			clocks = <&gcc GCC_QPIC_AHB_CLK>;
			clock-names = "bam_clk";
			#dma-cells = <1>;
			qcom,ee = <0>;
			qcom,bam-lite;
			status = "disabled";
		};

		qpic_nand: nand@79b0000 {
			compatible = "qcom,ipq5424-nand";
			reg = <0x79b0000 0x10000>;
			#address-cells = <1>;
			#size-cells = <0>;
			clocks = <&gcc GCC_QPIC_CLK>,
				 <&gcc GCC_QPIC_AHB_CLK>,
				 <&gcc GCC_QPIC_IO_MACRO_CLK>;
			clock-names = "core", "aon", "io_macro";

			dmas = <&qpic_bam 0>,
			       <&qpic_bam 1>,
			       <&qpic_bam 2>,
			       <&qpic_bam 3>;
			dma-names = "tx", "rx", "cmd", "sts";

			qcom,io_macro_max_clk = <320000000>;
			qcom,io_macro_clk_rates = <24000000 100000000 200000000 \
						   320000000>;

			pinctrl-0 = <&qspi_default_state>;
			pinctrl-names = "default";

			status = "disabled";
			nandcs@0 {
				reg = <0>;
				#address-cells = <1>;
				#size-cells = <1>;

				nand-ecc-strength = <8>;
				nand-ecc-step-size = <512>;
				nand-bus-width = <8>;
			};
		};

		ess-uniphy@7a00000 {
			compatible = "qcom,ess-uniphy";
			reg = <0x7a00000 0x30000>;
			uniphy_access_mode = "local bus";
			nvmem-cells = <&uniphy0_disable>, <&uniphy1_disable>, <&uniphy2_disable>;
			nvmem-cell-names = "uniphy0_disable", "uniphy1_disable", "uniphy2_disable";
		};

		edma@3ab00000 {
			compatible = "qcom,edma";
#ifdef __CONFIG_IO_COHERENCY__
			dma-coherent;
#endif
			reg = <0x3ab00000 0xef800>;
			reg-names = "edma-reg-base";
			resets = <&nsscc NSS_CC_PPE_EDMA_CLK_ARES>,
			       <&nsscc NSS_CC_PPE_EDMA_CFG_CLK_ARES>;
			reset-names = "edma_rst",
				"edma_cfg_rst";
			clocks = <&nsscc NSS_CC_NSS_CSR_CLK>,
				<&nsscc NSS_CC_NSSNOC_NSS_CSR_CLK>,
				<&nsscc NSS_CC_CE_APB_CLK>,
				<&nsscc NSS_CC_CE_AXI_CLK>,
				<&nsscc NSS_CC_NSSNOC_CE_APB_CLK>,
				<&nsscc NSS_CC_NSSNOC_CE_AXI_CLK>,
				<&nsscc NSS_CC_PPE_EDMA_CLK>,
				<&gcc GCC_NSS_TS_CLK>,
				<&gcc GCC_NSSCC_CLK>,
				<&gcc GCC_NSSCFG_CLK>,
				<&gcc GCC_NSSNOC_ATB_CLK>,
				<&gcc GCC_NSSNOC_NSSCC_CLK>,
				<&gcc GCC_NSSNOC_MEMNOC_CLK>,
				<&gcc GCC_NSSNOC_MEMNOC_1_CLK>,
				<&gcc GCC_NSSNOC_PCNOC_1_CLK>,
				<&gcc GCC_NSSNOC_QOSGEN_REF_CLK>,
				<&gcc GCC_NSSNOC_SNOC_1_CLK>,
				<&gcc GCC_NSSNOC_SNOC_CLK>,
				<&gcc GCC_NSSNOC_TIMEOUT_REF_CLK>,
				<&gcc GCC_NSSNOC_XO_DCD_CLK>;
			clock-names = "nss-csr-clk", "nss-nssnoc-csr-clk", "nss-ce-apb-clk",
				"nss-ce-axi-clk", "nss-nssnoc-ce-apb-clk", "nss-nssnoc-ce-axi-clk", "nss-edma-clk",
				"nss-ts-clk", "nss-nsscc-clk", "nss-nsscfg-clk", "nss-nssnoc-atb-clk",
				"nss-nssnoc-nsscc-clk", "nss-nssnoc-memnoc-clk", "nss-nssnoc-mem-noc-1-clk",
				"nss-nssnoc-pcnoc-1-clk", "nss-nssnoc-qosgen-ref-clk", "nss-nssnoc-snoc-1-clk",
				"nss-nssnoc-snoc-clk", "nss-nssnoc-timeout-ref-clk", "nss-nssnoc-xo-dcd-clk";

#ifdef __CONFIG_IO_COHERENCY__
			nss_noc {
				prop-name = "nss_noc";
				secure-write;
				reg-base = <0x01D80000>;
				reg-offset = <0x00005138 0x44410>,	/* CE Type LUT lower bits */
						<0x00005108 0x100>,	/* CE Main control lower bits */
						<0x00005238 0x44410>,	/* PPE Type LUT lower bits */
						<0x00005208 0x100>;	/* PPE Main control low */
			};

			nss_llcc {
				prop-name = "llcc_cache";
				/* denotes the data to be written into respective Cache Registers */
				cache_val = <0x83e02>,		/* RxDesc Cache registers value */
						<0x1f>,		/* TxCmpl Cache registers value */
						<0x20000a5>,	/* Cache Index LUT register value */
						<0x222ff>,	/* AxCache Overide register value */
						<0x789f>;	/* Axiw Ctrl register value */
			};
#endif
                };

		nss-ppe {
			compatible = "qcom,nss-ppe";
#ifdef __CONFIG_IO_COHERENCY__
			dma-coherent;
#endif
		};

		eip: eip196@39800000 {
			compatible = "qcom,eip";
#ifdef __CONFIG_IO_COHERENCY__
			dma-coherent;
#endif
			reg-names = "eip_pbase";
			reg = <0x39800000 0x7ffff>;
			reg_offset = <0x80000>;
			ranges;
			clocks = <&nsscc NSS_CC_EIP_CLK>,
			       <&nsscc NSS_CC_NSSNOC_EIP_CLK>;
			clock-names = "eip_clk", "eip_nocclk";
			clock-frequency = /bits/ 64 <375000000 375000000>;
			status = "ok";
			nvmem-cells = <&nss_disable>;

			interrupts = <GIC_SPI 230 IRQ_TYPE_LEVEL_HIGH>,
				   <GIC_SPI 231 IRQ_TYPE_LEVEL_HIGH>,
				   <GIC_SPI 232 IRQ_TYPE_LEVEL_HIGH>,
				   <GIC_SPI 233 IRQ_TYPE_LEVEL_HIGH>;

			dma0 {
				tx_cpu = /bits/ 8 <0>;
				rx_cpu = /bits/ 8 <0>;
				ring-name = "lookaside";
				ring-id = /bits/ 8 <0>;
			};

			dma1 {
				tx_cpu = /bits/ 8 <1>;
				rx_cpu = /bits/ 8 <1>;
				ring-name = "lookaside";
				ring-id = /bits/ 8 <1>;
			};

			dma2 {
				tx_cpu = /bits/ 8 <2>;
				rx_cpu = /bits/ 8 <2>;
				ring-name = "lookaside";
				ring-id = /bits/ 8 <2>;
			};

			dma3 {
				tx_cpu = /bits/ 8 <3>;
				rx_cpu = /bits/ 8 <3>;
				ring-name = "lookaside";
				ring-id = /bits/ 8 <3>;
			};

#ifdef __CONFIG_IO_COHERENCY__
			eip_ioc {
				prop-name = "eip_ioc";
				secure-write;
				reg-base = <0x01D80000>;
				reg-offset = <0x000051B8 0x44410>,	/* EIP196 Type LUT lower bits */
						<0x00005188 0x100>;	/* EIP196 Main control low */
			};
#endif
		};

		eip_crypto: eip_crypto {
			compatible = "qcom,eip_crypto";
			status = "ok";
		};

		apcs_glb: mailbox@f400004 {
			compatible = "qcom,ipq5424-apcs-global";
			reg = <0xf400004 0x6000>;
			#clock-cells = <1>;
			#mbox-cells = <1>;
		};

		qmp_tmel: qmp-tmel@32090000 {
			compatible = "qti,tmel-qmp-mbox";
			reg = <0x32090000 0x20>,
			      <0x32091000 0x20>;
			reg-names = "mcore", "ucore";

			interrupts = <GIC_SPI 126 IRQ_TYPE_EDGE_RISING>;
			max_pkt_size = <0x18>;

			mboxes = <&apcs_glb 20>;
			qti,early-boot;
			#mbox-cells = <1>;
			status = "disabled";
		};

		seccrypt: qcom,seccrypt {
			compatible = "qcom,seccrypt";
			status = "okay";
		};

		tmelcom: qcom,tmelcom-qmp-client {
			compatible = "qcom,tmelcom-qmp-client";
			mboxes = <&qmp_tmel 0>;
			status = "disabled";
		};

		watchdog: watchdog@f410000 {
			compatible = "qcom,apss-wdt-ipq5424", "qcom,kpss-wdt";
			reg = <0xf410000 0x1000>;
			interrupts = <GIC_SPI 0 IRQ_TYPE_EDGE_RISING>;
			clocks = <&sleep_clk>;
			timeout-sec = <30>;
			qcom,restart-reason = <&imem 0x7b0 0x5>;
		};

		noc_lat_bw {
			compatible = "qcom,noc-tprobe-driver";
		};

		apss_comp {
			compatible = "qcom,apss-comp-driver";
			reg = <0xAC0A00 0x1000>,<0xAC2000 0x1000>, <0xAC9000 0x1000>;
			reg-names = "tenureprobe-base", "traceprobe-base", "eventcounter-base";
			hist_bin_width = <0x8>;
			ddr_addr_min_low = <0x80000000>;
			ddr_addr_min_high = <0x00000000>;
			ddr_addr_max_low = <0x80000000>;
			ddr_addr_max_high = <0x00000009>;
			trace_probe_extid_base = <0x4000>; /* BID=2: PID=0: MID=0 of APSS */
			trace_probe_extid_mask = <0xff00>;
			ec_ctl1_base_val = <0x472>;
			status = "ok";
		};

		ppe_comp {
			compatible = "qcom,ppe-comp-driver";
			reg = <0x1D8C000 0x1000>,<0x1D8A800 0x1000>, <0x1D8B000 0x1000>;
			reg-names = "tenureprobe-base", "traceprobe-base", "eventcounter-base";
			hist_bin_width = <0x8>;
			ddr_addr_min_low = <0x80000000>;
			ddr_addr_min_high = <0x00000000>;
			ddr_addr_max_low = <0x80000000>;
			ddr_addr_max_high = <0x00000009>;
			trace_probe_extid_base = <0x300>; /* BID=0: PID=3: MID=0 of PPE */
			trace_probe_extid_mask = <0x1f00>;
			ec_ctl1_base_val = <0x411>;
			status = "ok";
		};

		q6_comp {
			compatible = "qcom,q6-comp-driver";
			reg = <0xAC0800 0x1000>,<0xAC2000 0x1000>, <0xAC9000 0x1000>;
			reg-names = "tenureprobe-base", "traceprobe-base", "eventcounter-base";
			hist_bin_width = <0x8>;
			ddr_addr_min_low = <0x80000000>;
			ddr_addr_min_high = <0x00000000>;
			ddr_addr_max_low = <0x80000000>;
			ddr_addr_max_high = <0x00000009>;
			trace_probe_extid_base = <0x4100>; /* BID=2: PID=0: MID=0 of APSS */
			trace_probe_extid_mask = <0xff00>;
			ec_ctl1_base_val = <0x472>;
			status = "ok";
		};

		pcie1_lane0_comp {
			compatible = "qcom,pcie1-lane0-comp-driver";
			reg = <0x601200 0x1000>,<0x602000 0x1000>, <0x603000 0x1000>;
			reg-names = "tenureprobe-base", "traceprobe-base", "eventcounter-base";
			hist_bin_width = <0x8>;
			ddr_addr_min_low = <0x80000000>;
			ddr_addr_min_high = <0x00000000>;
			ddr_addr_max_low = <0x80000000>;
			ddr_addr_max_high = <0x00000009>;
			trace_probe_extid_base = <0x4C00>; /* BID=2: PID=0: MID=0 of APSS */
			trace_probe_extid_mask = <0xff00>;
			ec_ctl1_base_val = <0x404>;
			status = "disabled";
		};

		pcie1_lane1_comp {
			compatible = "qcom,pcie1-lane1-comp-driver";
			reg = <0x601400 0x1000>,<0x602000 0x1000>, <0x603000 0x1000>;
			reg-names = "tenureprobe-base", "traceprobe-base", "eventcounter-base";
			hist_bin_width = <0x8>;
			ddr_addr_min_low = <0x80000000>;
			ddr_addr_min_high = <0x00000000>;
			ddr_addr_max_low = <0x80000000>;
			ddr_addr_max_high = <0x00000009>;
			trace_probe_extid_base = <0x4E00>; /* BID=2: PID=0: MID=0 of APSS */
			trace_probe_extid_mask = <0xff00>;
			ec_ctl1_base_val = <0x404>;
			status = "disabled";
		};

		pcie2_lane0_comp {
			compatible = "qcom,pcie2-lane0-comp-driver";
			reg = <0x601600 0x1000>,<0x602000 0x1000>, <0x603000 0x1000>;
			reg-names = "tenureprobe-base", "traceprobe-base", "eventcounter-base";
			hist_bin_width = <0x8>;
			ddr_addr_min_low = <0x80000000>;
			ddr_addr_min_high = <0x00000000>;
			ddr_addr_max_low = <0x80000000>;
			ddr_addr_max_high = <0x00000009>;
			trace_probe_extid_base = <0x4D00>; /* BID=2: PID=0: MID=0 of APSS */
			trace_probe_extid_mask = <0xff00>;
			ec_ctl1_base_val = <0x404>;
			status = "ok";
		};

		pcie2_lane1_comp {
			compatible = "qcom,pcie2-lane1-comp-driver";
			reg = <0x601800 0x1000>,<0x602000 0x1000>, <0x603000 0x1000>;
			reg-names = "tenureprobe-base", "traceprobe-base", "eventcounter-base";
			hist_bin_width = <0x8>;
			ddr_addr_min_low = <0x80000000>;
			ddr_addr_min_high = <0x00000000>;
			ddr_addr_max_low = <0x80000000>;
			ddr_addr_max_high = <0x00000009>;
			trace_probe_extid_base = <0x4F00>; /* BID=2: PID=0: MID=0 of APSS */
			trace_probe_extid_mask = <0xff00>;
			ec_ctl1_base_val = <0x404>;
			status = "ok";
		};

		hist_apss_comp {
			compatible = "qcom,hist-apss-comp-driver";
			reg = <0xAC0C00 0x1000>, <0xACB800 0x1000>;
			reg-names = "histprobe-base", "histctrl-base";
			hist_bin_width = <0x8>;
			ddr_addr_min_low = <0x80000000>;
			ddr_addr_min_high = <0x00000000>;
			ddr_addr_max_low = <0x80000000>;
			ddr_addr_max_high = <0x00000009>;
			trace_probe_extid_base = <0x4000>; /* BID=2: PID=0: MID=0 of APSS */
			trace_probe_extid_mask = <0xff00>;
			ec_ctl1_base_val = <0x404>;
			status = "ok";
		};

		llcc_be_apss_comp {
			compatible = "qcom,llcc-be-apss-comp-driver";
			reg = <0x836000 0x2000>, <0x860000 0x2000>, <0x83C000 0x2000>, <0x824000 0x2000>;
			reg-names = "llcc-perfmon-base", "llcc-beac-base", "llcc-berc-base", "llcc-trp-prof-filter-base";
			hist_bin_width = <0x8>;
			ddr_addr_min_low = <0x80000000>;
			ddr_addr_min_high = <0x00000000>;
			ddr_addr_max_low = <0x80000000>;
			ddr_addr_max_high = <0x00000009>;
			trace_probe_extid_base = <0x4000>; /* BID=2: PID=0: MID=0 of APSS */
			trace_probe_extid_mask = <0xff00>;
			ec_ctl1_base_val = <0x404>;
			status = "ok";
		};

		sysnoc_ce_edpd_comp {
			compatible = "qcom,sysnoc-ce-edpd-comp-driver";
			reg = <0x581800 0x1000>,<0x584000 0x1000>, <0x585000 0x1000>;
			reg-names = "tenureprobe-base", "traceprobe-base", "eventcounter-base";
			hist_bin_width = <0x3200008>;
			ddr_addr_min_low = <0x80000000>;
			ddr_addr_min_high = <0x00000000>;
			ddr_addr_max_low = <0x80000000>;
			ddr_addr_max_high = <0x00000009>;
			trace_probe_extid_base = <0xE000>; /* BID=2: PID=0: MID=0 of APSS */
			trace_probe_extid_mask = <0xE000>;
			ec_ctl1_base_val = <0x11>;
			status = "ok";
		};

		sysnoc_wcss_comp {
			compatible = "qcom,sysnoc-wcss-comp-driver";
			reg = <0x581A00 0x1000>,<0x584000 0x1000>, <0x585000 0x1000>;
			reg-names = "tenureprobe-base", "traceprobe-base", "eventcounter-base";
			hist_bin_width = <0x3200008>;
			ddr_addr_min_low = <0x80000000>;
			ddr_addr_min_high = <0x00000000>;
			ddr_addr_max_low = <0x80000000>;
			ddr_addr_max_high = <0x00000009>;
			trace_probe_extid_base = <0x8000>; /* BID=2: PID=0: MID=0 of APSS */
			trace_probe_extid_mask = <0xE000>;
			ec_ctl1_base_val = <0x11>;
			status = "ok";
		};

		timer@f420000 {
			compatible = "arm,armv7-timer-mem";
			reg = <0xf420000 0x1000>;
			#address-cells = <1>;
			#size-cells = <1>;
			ranges;

			frame@f421000 {
				reg = <0xf421000 0x1000>,
				      <0xf422000 0x1000>;
				interrupts = <GIC_SPI 8 IRQ_TYPE_LEVEL_HIGH>,
					     <GIC_SPI 6 IRQ_TYPE_LEVEL_HIGH>;
				frame-number = <0>;
			};

			frame@f423000 {
				reg = <0xf423000 0x1000>;
				interrupts = <GIC_SPI 9 IRQ_TYPE_LEVEL_HIGH>;
				frame-number = <1>;
				status = "disabled";
			};

			frame@f425000 {
				reg = <0xf425000 0x1000>,
				      <0xf426000 0x1000>;
				interrupts = <GIC_SPI 10 IRQ_TYPE_LEVEL_HIGH>;
				frame-number = <2>;
				status = "disabled";
			};

			frame@f427000 {
				reg = <0xf427000 0x1000>;
				interrupts = <GIC_SPI 11 IRQ_TYPE_LEVEL_HIGH>;
				frame-number = <3>;
				status = "disabled";
			};

			frame@f429000 {
				reg = <0xf429000 0x1000>;
				interrupts = <GIC_SPI 12 IRQ_TYPE_LEVEL_HIGH>;
				frame-number = <4>;
				status = "disabled";
			};

			frame@f42b000 {
				reg = <0xf42b000 0x1000>;
				interrupts = <GIC_SPI 13 IRQ_TYPE_LEVEL_HIGH>;
				frame-number = <5>;
				status = "disabled";
			};

			frame@f42d000 {
				reg = <0xf42d000 0x1000>;
				interrupts = <GIC_SPI 14 IRQ_TYPE_LEVEL_HIGH>;
				frame-number = <6>;
				status = "disabled";
			};
		};

		/* 2L controller */
		pcie3: pcie@40000000 {
			compatible = "qcom,pcie-ipq5424";
			reg =  <0x40000000 0xf1d>,
			       <0x40000f20 0xa8>,
			       <0x40001000 0x1000>,
			       <0xf8000 0x3000>,
			       <0x40100000 0x1000>;
			reg-names = "dbi", "elbi", "atu", "parf", "config";
			device_type = "pci";
			linux,pci-domain = <3>;
			bus-range = <0x00 0xff>;
			num-lanes = <2>;
			#address-cells = <3>;
			#size-cells = <2>;
			axi-halt-val = <0x1e>; /* increase halt window size to 1GB */
			cal-status-offset = <0x2400000>;

			ranges = <0x81000000 0 0x40200000 0x40200000 0 0x00100000>,   /* downstream I/O */
				 <0x82000000 0 0x40300000 0x40300000 0 0x0fd00000>; /* non-prefetchable memory */

			#interrupt-cells = <1>;
			interrupt-map-mask = <0 0 0 0x7>;
			interrupt-map = <0 0 0 1 &intc 0 479 IRQ_TYPE_LEVEL_HIGH>, /* int_a */
					<0 0 0 2 &intc 0 480 IRQ_TYPE_LEVEL_HIGH>, /* int_b */
					<0 0 0 3 &intc 0 481 IRQ_TYPE_LEVEL_HIGH>, /* int_c */
					<0 0 0 4 &intc 0 482 IRQ_TYPE_LEVEL_HIGH>; /* int_d */

			interrupts = <GIC_SPI 478 IRQ_TYPE_LEVEL_HIGH>;
			interrupt-names = "global_irq";

			clocks = <&gcc GCC_PCIE3_AXI_M_CLK>,
				 <&gcc GCC_PCIE3_AXI_S_CLK>,
				 <&gcc GCC_PCIE3_AHB_CLK>,
				 <&gcc GCC_PCIE3_AUX_CLK>,
				 <&gcc GCC_PCIE3_AXI_S_BRIDGE_CLK>,
				 <&gcc GCC_PCIE3_RCHNG_CLK>;

			clock-names = "axi_m",
				      "axi_s",
				      "ahb",
				      "aux",
				      "axi_bridge",
				      "rchng";

			assigned-clocks = <&gcc GCC_PCIE3_AHB_CLK>,
					<&gcc GCC_PCIE3_AUX_CLK>,
					<&gcc GCC_PCIE3_AXI_M_CLK>,
					<&gcc GCC_PCIE3_AXI_S_BRIDGE_CLK>,
					<&gcc GCC_PCIE3_AXI_S_CLK>,
					<&gcc GCC_PCIE3_RCHNG_CLK>;

			assigned-clock-rates = <100000000>,
						<20000000>,
						<266666666>,
						<240000000>,
						<240000000>,
						<100000000>;

			resets = <&gcc GCC_PCIE3_PIPE_ARES>,
				 <&gcc GCC_PCIE3_CORE_STICKY_RESET>,
				 <&gcc GCC_PCIE3_AXI_M_ARES>,
				 <&gcc GCC_PCIE3_AXI_S_ARES>,
				 <&gcc GCC_PCIE3_AXI_M_STICKY_RESET>,
				 <&gcc GCC_PCIE3_AXI_S_STICKY_RESET>,
				 <&gcc GCC_PCIE3_AHB_ARES>,
				 <&gcc GCC_PCIE3_AUX_ARES>;

			reset-names = "pipe",
				      "sticky",
				      "axi_m",
				      "axi_s",
				      "axi_m_sticky",
				      "axi_s_sticky",
				      "ahb",
				      "aux";

			msi-parent = <&intc>;
			nvmem-cells = <&pcie3_disable>;

			pinctrl-0 = <&pcie3_default_state>;
			pinctrl-names = "default";

			phys = <&pcie3_lanes>;
			phy-names = "pciephy";

			status = "disabled";

			pcie3_rp {
				qcom,mhi@3 {
				secure-reg = <0x00610708 0x130100>, /* pcie3 Main Ctl Low */
						<0x00610738 0x44410>, /* pcie3 TrType LUT Low */
						<0x00610748 0x100>, /* pci3 dynattr Alloc Low */
						<0x00610750 0x7>; /*pci3 dynattr CacheIndexVal Low*/
				};
			};
		};

		/* 2L controller */
		pcie2: pcie@50000000 {
			compatible = "qcom,pcie-ipq5424";
			reg =  <0x50000000 0xf1d>,
			       <0x50000f20 0xa8>,
			       <0x50001000 0x1000>,
			       <0xf0000 0x3000>,
			       <0x50100000 0x1000>;
			reg-names = "dbi", "elbi", "atu", "parf", "config";
			device_type = "pci";
			linux,pci-domain = <2>;
			bus-range = <0x00 0xff>;
			num-lanes = <2>;
			#address-cells = <3>;
			#size-cells = <2>;
			axi-halt-val = <0x1e>; /* increase halt window size to 1GB */
			cal-status-offset = <0x2400000>;

			ranges = <0x81000000 0 0x50200000 0x50200000 0 0x00100000>,   /* downstream I/O */
				 <0x82000000 0 0x50300000 0x50300000 0 0x0fd00000>; /* non-prefetchable memory */

			#interrupt-cells = <1>;
			interrupt-map-mask = <0 0 0 0x7>;
			interrupt-map = <0 0 0 1 &intc 0 464 IRQ_TYPE_LEVEL_HIGH>, /* int_a */
					<0 0 0 2 &intc 0 465 IRQ_TYPE_LEVEL_HIGH>, /* int_b */
					<0 0 0 3 &intc 0 466 IRQ_TYPE_LEVEL_HIGH>, /* int_c */
					<0 0 0 4 &intc 0 467 IRQ_TYPE_LEVEL_HIGH>; /* int_d */

			interrupts = <GIC_SPI 463 IRQ_TYPE_LEVEL_HIGH>;
			interrupt-names = "global_irq";

			clocks = <&gcc GCC_PCIE2_AXI_M_CLK>,
				 <&gcc GCC_PCIE2_AXI_S_CLK>,
				 <&gcc GCC_PCIE2_AHB_CLK>,
				 <&gcc GCC_PCIE2_AUX_CLK>,
				 <&gcc GCC_PCIE2_AXI_S_BRIDGE_CLK>,
				 <&gcc GCC_PCIE2_RCHNG_CLK>;

			clock-names = "axi_m",
				      "axi_s",
				      "ahb",
				      "aux",
				      "axi_bridge",
				      "rchng";

			assigned-clocks = <&gcc GCC_PCIE2_AHB_CLK>,
					<&gcc GCC_PCIE2_AUX_CLK>,
					<&gcc GCC_PCIE2_AXI_M_CLK>,
					<&gcc GCC_PCIE2_AXI_S_BRIDGE_CLK>,
					<&gcc GCC_PCIE2_AXI_S_CLK>,
					<&gcc GCC_PCIE2_RCHNG_CLK>;

			assigned-clock-rates = <100000000>,
						<20000000>,
						<266666666>,
						<240000000>,
						<240000000>,
						<100000000>;

			resets = <&gcc GCC_PCIE2_PIPE_ARES>,
				 <&gcc GCC_PCIE2_CORE_STICKY_RESET>,
				 <&gcc GCC_PCIE2_AXI_M_ARES>,
				 <&gcc GCC_PCIE2_AXI_S_ARES>,
				 <&gcc GCC_PCIE2_AXI_M_STICKY_RESET>,
				 <&gcc GCC_PCIE2_AXI_S_STICKY_RESET>,
				 <&gcc GCC_PCIE2_AHB_ARES>,
				 <&gcc GCC_PCIE2_AUX_ARES>;

			reset-names = "pipe",
				      "sticky",
				      "axi_m",
				      "axi_s",
				      "axi_m_sticky",
				      "axi_s_sticky",
				      "ahb",
				      "aux";

			msi-parent = <&intc>;
			nvmem-cells = <&pcie2_disable>;

			pinctrl-0 = <&pcie2_default_state>;
			pinctrl-names = "default";

			phys = <&pcie2_lanes>;
			phy-names = "pciephy";

			status = "disabled";

			pcie2_rp {
				qcom,mhi@2 {
				secure-reg = <0x00610608 0x130100>, /* pcie2 Main Ctl Low */
						<0x00610638 0x44410>, /* pcie2 TrType LUT Low */
						<0x00610648 0x100>, /* pci2 dynattr Alloc Low */
						<0x00610650 0x6>; /*pci2 dynattr CacheIndexVal Low*/
				};
			};
		};

		/* 1L controller */
		pcie1: pcie@60000000 {
			compatible = "qcom,pcie-ipq5424";
			reg =  <0x60000000 0xf1d>,
			       <0x60000f20 0xa8>,
			       <0x60001000 0x1000>,
			       <0x88000 0x3000>,
			       <0x60100000 0x1000>;
			reg-names = "dbi", "elbi", "atu", "parf", "config";
			device_type = "pci";
			linux,pci-domain = <1>;
			bus-range = <0x00 0xff>;
			num-lanes = <1>;
			#address-cells = <3>;
			#size-cells = <2>;
			axi-halt-val = <0x1e>; /* increase halt window size to 1GB */
			cal-status-offset = <0x2400000>;

			ranges = <0x81000000 0 0x60200000 0x60200000 0 0x00100000>,   /* downstream I/O */
				 <0x82000000 0 0x60300000 0x60300000 0 0x0fd00000>; /* non-prefetchable memory */

			#interrupt-cells = <1>;
			interrupt-map-mask = <0 0 0 0x7>;
			interrupt-map = <0 0 0 1 &intc 0 449 IRQ_TYPE_LEVEL_HIGH>, /* int_a */
					<0 0 0 2 &intc 0 450 IRQ_TYPE_LEVEL_HIGH>, /* int_b */
					<0 0 0 3 &intc 0 451 IRQ_TYPE_LEVEL_HIGH>, /* int_c */
					<0 0 0 4 &intc 0 452 IRQ_TYPE_LEVEL_HIGH>; /* int_d */

			interrupts = <GIC_SPI 448 IRQ_TYPE_LEVEL_HIGH>;
			interrupt-names = "global_irq";

			clocks = <&gcc GCC_PCIE1_AXI_M_CLK>,
				 <&gcc GCC_PCIE1_AXI_S_CLK>,
				 <&gcc GCC_PCIE1_AHB_CLK>,
				 <&gcc GCC_PCIE1_AUX_CLK>,
				 <&gcc GCC_PCIE1_AXI_S_BRIDGE_CLK>,
				 <&gcc GCC_PCIE1_RCHNG_CLK>;

			clock-names = "axi_m",
				      "axi_s",
				      "ahb",
				      "aux",
				      "axi_bridge",
				      "rchng";

			assigned-clocks = <&gcc GCC_PCIE1_AHB_CLK>,
					<&gcc GCC_PCIE1_AUX_CLK>,
					<&gcc GCC_PCIE1_AXI_M_CLK>,
					<&gcc GCC_PCIE1_AXI_S_BRIDGE_CLK>,
					<&gcc GCC_PCIE1_AXI_S_CLK>,
					<&gcc GCC_PCIE1_RCHNG_CLK>;

			assigned-clock-rates = <100000000>,
						<20000000>,
						<240000000>,
						<240000000>,
						<240000000>,
						<100000000>;

			resets = <&gcc GCC_PCIE1_PIPE_ARES>,
				 <&gcc GCC_PCIE1_CORE_STICKY_RESET>,
				 <&gcc GCC_PCIE1_AXI_M_ARES>,
				 <&gcc GCC_PCIE1_AXI_S_ARES>,
				 <&gcc GCC_PCIE1_AXI_M_STICKY_RESET>,
				 <&gcc GCC_PCIE1_AXI_S_STICKY_RESET>,
				 <&gcc GCC_PCIE1_AHB_ARES>,
				 <&gcc GCC_PCIE1_AUX_ARES>;

			reset-names = "pipe",
				      "sticky",
				      "axi_m",
				      "axi_s",
				      "axi_m_sticky",
				      "axi_s_sticky",
				      "ahb",
				      "aux";

			msi-parent = <&intc>;
			nvmem-cells = <&pcie1_disable>;

			pinctrl-0 = <&pcie1_default_state>;
			pinctrl-names = "default";

			phys = <&pcie1_lanes>;
			phy-names = "pciephy";

			status = "disabled";

			pcie1_rp {
				qcom,mhi@1 {
				secure-reg = <0x00610508 0x130100>, /* pcie1 Main Ctl Low */
						<0x00610538 0x44410>, /* pcie1 TrType LUT Low */
						<0x00610548 0x100>, /* pci1 dynattr Alloc Low */
						<0x00610550 0x7>; /*pci1 dynattr CacheIndexVal Low*/
				};
			};
		};

		/* 1L controller */
		pcie0: pcie@70000000 {
			compatible = "qcom,pcie-ipq5424";
			reg =  <0x70000000 0xf1d>,
			       <0x70000f20 0xa8>,
			       <0x70001000 0x1000>,
			       <0x80000 0x3000>,
			       <0x70100000 0x1000>;
			reg-names = "dbi", "elbi", "atu", "parf", "config";
			device_type = "pci";
			linux,pci-domain = <0>;
			bus-range = <0x00 0xff>;
			num-lanes = <1>;
			#address-cells = <3>;
			#size-cells = <2>;
			axi-halt-val = <0x1e>; /* increase halt window size to 1GB */
			cal-status-offset = <0x2400000>;

			ranges = <0x81000000 0 0x70200000 0x70200000 0 0x00100000>,   /* downstream I/O */
				 <0x82000000 0 0x70300000 0x70300000 0 0x0fd00000>; /* non-prefetchable memory */

			#interrupt-cells = <1>;
			interrupt-map-mask = <0 0 0 0x7>;
			interrupt-map = <0 0 0 1 &intc 0 434 IRQ_TYPE_LEVEL_HIGH>, /* int_a */
					<0 0 0 2 &intc 0 435 IRQ_TYPE_LEVEL_HIGH>, /* int_b */
					<0 0 0 3 &intc 0 436 IRQ_TYPE_LEVEL_HIGH>, /* int_c */
					<0 0 0 4 &intc 0 437 IRQ_TYPE_LEVEL_HIGH>; /* int_d */

			interrupts = <GIC_SPI 433 IRQ_TYPE_LEVEL_HIGH>;
			interrupt-names = "global_irq";

			clocks = <&gcc GCC_PCIE0_AXI_M_CLK>,
				 <&gcc GCC_PCIE0_AXI_S_CLK>,
				 <&gcc GCC_PCIE0_AHB_CLK>,
				 <&gcc GCC_PCIE0_AUX_CLK>,
				 <&gcc GCC_PCIE0_AXI_S_BRIDGE_CLK>,
				 <&gcc GCC_PCIE0_RCHNG_CLK>;

			clock-names = "axi_m",
				      "axi_s",
				      "ahb",
				      "aux",
				      "axi_bridge",
				      "rchng";

			assigned-clocks = <&gcc GCC_PCIE0_AHB_CLK>,
					<&gcc GCC_PCIE0_AUX_CLK>,
					<&gcc GCC_PCIE0_AXI_M_CLK>,
					<&gcc GCC_PCIE0_AXI_S_BRIDGE_CLK>,
					<&gcc GCC_PCIE0_AXI_S_CLK>,
					<&gcc GCC_PCIE0_RCHNG_CLK>;

			assigned-clock-rates = <100000000>,
						<20000000>,
						<240000000>,
						<240000000>,
						<240000000>,
						<100000000>;

			resets = <&gcc GCC_PCIE0_PIPE_ARES>,
				 <&gcc GCC_PCIE0_CORE_STICKY_RESET>,
				 <&gcc GCC_PCIE0_AXI_M_ARES>,
				 <&gcc GCC_PCIE0_AXI_S_ARES>,
				 <&gcc GCC_PCIE0_AXI_M_STICKY_RESET>,
				 <&gcc GCC_PCIE0_AXI_S_STICKY_RESET>,
				 <&gcc GCC_PCIE0_AHB_ARES>,
				 <&gcc GCC_PCIE0_AUX_ARES>;

			reset-names = "pipe",
				      "sticky",
				      "axi_m",
				      "axi_s",
				      "axi_m_sticky",
				      "axi_s_sticky",
				      "ahb",
				      "aux";

			msi-parent = <&intc>;
			nvmem-cells = <&pcie0_disable>;

			pinctrl-0 = <&pcie0_default_state>;
			pinctrl-names = "default";

			phys = <&pcie0_lanes>;
			phy-names = "pciephy";

			status = "disabled";

			pcie0_rp {
				qcom,mhi@0 {
				secure-reg = <0x00610408 0x130100>, /* pcie0 Main Ctl Low */
						<0x00610438 0x44410>, /* pcie0 TrType LUT Low */
						<0x00610448 0x100>, /* pci0 dynattr Alloc Low */
						<0x00610450 0x6>; /*pci0 dynattr CacheIndexVal Low*/
				};
			};
		};

		wifi0: wifi@c0000000 {
			compatible = "qcom,cnss-qca5424", "qcom,ipq5424-wifi";
			qcom,userpd-subsys-name = "q6v5_wcss_userpd1";
			qcom,mm_cal_support = "okay";
		#ifdef __CONFIG_IO_COHERENCY__
			dma-coherent;
		#endif
			reg = <0xc000000 0x1000000>;
		#ifdef __IPQ_MEM_PROFILE_256_MB__
			qcom,tgt-mem-mode = <2>;
		#elif __IPQ_MEM_PROFILE_512_MB__
			qcom,tgt-mem-mode = <1>;
		#else
			qcom,tgt-mem-mode = <0>;
		#endif
			qcom,rproc = <&q6v5_wcss>;
			qcom,bdf-addr = <0x8b240000 0x8b240000 0x8b240000
					 0x0 0x0 0x0>;
			qcom,caldb-addr = <0x8d300000 0x8d300000 0x0
					   0x0 0x0 0x0>;
			qcom,caldb-size = <0x600000>;
			interrupts = <0 0 0>,
				<0 0 0>,
				<0 0 0>,
				<0 0 0>,
				<0 559 1>, /* misc-pulse1 */
				<0 560 1>, /* misc-latch */
				<0 561 1>, /* sw-exception */
				<0 518 1>, /* ce0 */
				<0 519 1>, /* ce1 */
				<0 520 1>, /* ce2 */
				<0 521 1>, /* ce3 */
				<0 522 1>, /* ce4 */
				<0 523 1>, /* ce5 */
				<0 524 1>, /* ce6 */
				<0 525 1>, /* ce7 */
				<0 526 1>, /* ce8 */
				<0 527 1>, /* ce9 */
				<0 528 1>, /* ce10 */
				<0 529 1>, /* ce11 */
				<0 574 1>, /* host2wbm-desc-feed */
				<0 578 1>, /* host2reo-re-injection */
				<0 576 1>, /* host2reo-command */
				<0 627 1>, /* host2rxdma-monitor-ring1 */
				<0 540 1>, /* reo2ost-exception */
				<0 549 1>, /* wbm2host-rx-release */
				<0 580 1>, /* reo2host-status */
				<0 537 1>, /* reo2host-destination-ring4 */
				<0 536 1>, /* reo2host-destination-ring3 */
				<0 535 1>, /* reo2host-destination-ring2 */
				<0 534 1>, /* reo2host-destination-ring1 */
				<0 571 1>, /* rxdma2host-monitor-destination-mac3 */
				<0 571 1>, /* rxdma2host-monitor-destination-mac2 */
				<0 567 1>, /* rxdma2host-monitor-destination-mac1 */
				<0 637 1>, /* host2rxdma-host-buf-ring-mac3 */
				<0 637 1>, /* host2rxdma-host-buf-ring-mac2 */
				<0 632 1>, /* host2rxdma-host-buf-ring-mac1 */
				<0 590 1>, /* host2tcl-input-ring4 */
				<0 583 1>, /* host2tcl-input-ring3 */
				<0 582 1>, /* host2tcl-input-ring2 */
				<0 581 1>, /* host2tcl-input-ring1 */
				<0 533 1>, /* wbm2host-tx-completions-ring4 */
				<0 532 1>, /* wbm2host-tx-completions-ring3 */
				<0 531 1>, /* wbm2host-tx-completions-ring2 */
				<0 530 1>, /* wbm2host-tx-completions-ring1 */
				<0 626 1>, /* host2tx-monitor-ring1 */
				<0 569 1>, /* txmon2host-monitor-destination-mac3 */
				<0 569 1>, /* txmon2host-monitor-destination-mac2 */
				<0 565 1>, /* txmon2host-monitor-destination-mac1 */
				<0 502 1>, /* umac_reset */
				<0 558 1>, /* reo2ppe1 */
				<0 586 1>, /* reo2ppe */
				<0 550 1>, /* ppe_wbm_rel */
				<0 562 1>, /* ppe2tcl */
				/* Unused Interrupts - Mapping these interrupts to ce11 interrupt number since ce11 is unused */
				<0 529 1>, /* host2rxdma-monitor-ring3 */
				<0 529 1>, /* host2rxdma-monitor-ring2 */
				<0 529 1>, /* ppdu-end-interrupts-mac3 */
				<0 529 1>, /* ppdu-end-interrupts-mac2 */
				<0 529 1>, /* ppdu-end-interrupts-mac1 */
				<0 529 1>, /* rxdma2host-monitor-status-ring-mac3 */
				<0 529 1>, /* rxdma2host-monitor-status-ring-mac2 */
				<0 529 1>, /* rxdma2host-monitor-status-ring-mac1 */
				<0 529 1>, /* rxdma2host-destination-ring-mac3 */
				<0 529 1>, /* rxdma2host-destination-ring-mac2 */
				<0 529 1>; /* rxdma2host-destination-ring-mac1 */

			interrupts-extended = <&wcss_smp2p_in 8 0>,
				<&wcss_smp2p_in 9 0>,
				<&wcss_smp2p_in 12 0>,
				<&wcss_smp2p_in 11 0>;

			interrupt-names = "fatal",
				"ready",
				"spawn",
				"stop-ack",
				"misc-pulse1",
				"misc-latch",
				"sw-exception",
				"ce0",
				"ce1",
				"ce2",
				"ce3",
				"ce4",
				"ce5",
				"ce6",
				"ce7",
				"ce8",
				"ce9",
				"ce10",
				"ce11",
				"host2wbm-desc-feed",
				"host2reo-re-injection",
				"host2reo-command",
				"host2rxdma-monitor-ring1",
				"reo2ost-exception",
				"wbm2host-rx-release",
				"reo2host-status",
				"reo2host-destination-ring4",
				"reo2host-destination-ring3",
				"reo2host-destination-ring2",
				"reo2host-destination-ring1",
				"rxdma2host-monitor-destination-mac3",
				"rxdma2host-monitor-destination-mac2",
				"rxdma2host-monitor-destination-mac1",
				"host2rxdma-host-buf-ring-mac3",
				"host2rxdma-host-buf-ring-mac2",
				"host2rxdma-host-buf-ring-mac1",
				"host2tcl-input-ring4",
				"host2tcl-input-ring3",
				"host2tcl-input-ring2",
				"host2tcl-input-ring1",
				"wbm2host-tx-completions-ring4",
				"wbm2host-tx-completions-ring3",
				"wbm2host-tx-completions-ring2",
				"wbm2host-tx-completions-ring1",
				"host2tx-monitor-ring1",
				"txmon2host-monitor-destination-mac3",
				"txmon2host-monitor-destination-mac2",
				"txmon2host-monitor-destination-mac1",
				"umac_reset",
				"reo2ppe1",
				"reo2ppe",
				"ppe_wbm_rel",
				"ppe2tcl",
				/* Unused Interrupts */
				"host2rxdma-monitor-ring3",
				"host2rxdma-monitor-ring2",
				"ppdu-end-interrupts-mac3",
				"ppdu-end-interrupts-mac2",
				"ppdu-end-interrupts-mac1",
				"rxdma2host-monitor-status-ring-mac3",
				"rxdma2host-monitor-status-ring-mac2",
				"rxdma2host-monitor-status-ring-mac1",
				"rxdma2host-destination-ring-mac3",
				"rxdma2host-destination-ring-mac2",
				"rxdma2host-destination-ring-mac1";
			/* 42 indicates GPIO number for LED_2G.
			 * 0 indicates that the GPIO is active high.
			 */
			led-gpio = <&tlmm 42 GPIO_ACTIVE_HIGH>;
			qcom,pta-num = <0>;
			qcom,coex-mode = <0x2>;
			qcom,bt-active-time = <0x18>;
			qcom,bt-priority-time = <0x12>;
			qcom,coex-algo = <0x2>;
			qcom,pta-priority = <0x80800505>;
			qcom,smem-states = <&wcss_smp2p_out 8>,
					   <&wcss_smp2p_out 9>,
					   <&wcss_smp2p_out 10>;
			qcom,smem-state-names = "shutdown",
						"stop",
						"spawn";
#if defined(__RPROC_DISABLE_MPD_SUPPORT__)
			dump-region = <&q6_ipq5424_data>,
					<&m3_dump>,
					<&q6_etr_region>,
					<&q6_ipq5424_caldb>,
					<&mlo_global_mem0>;
#endif
			status = "disabled";
		};

		wifi1: wifi1@f00000 {
			compatible  = "qcom,cnss-qcn9224";
		#ifdef __CONFIG_IO_COHERENCY__
			dma-coherent;
		#endif
			qcom,wlan-ramdump-dynamic = <0x600000>;
			qca,auto-restart;
			interrupt-bmap = <0x100512>;
			node_id = <0>;
		#ifdef __IPQ_MEM_PROFILE_512_MB__
			/* qcn9224 tgt-mem-mode=1 layout - 37MB
			 * +=========+==============+=========+
			 * |  Region | Start Offset |   Size  |
			 * +---------+--------------+---------+
			 * | HREMOTE |  0x8d900000  |   20MB  |
			 * +---------+--------------+---------+
			 * |  Caldb  |  0x8ed00000  |   8MB   |
			 * +---------+--------------+---------+
			 * | M3 Dump |  0x8f500000  |   1MB   |
			 * +---------+--------------+---------+
			 * |   ETR   |  0x8f600000  |   1MB   |
			 * +---------+--------------+---------+
			 * |Pageable |  0x8f700000  |   7MB   |
			 * +==================================+
			 */
			base-addr = <0x8d900000>;
			caldb-addr = <0x8ed00000>;
			m3-dump-addr = <0x8f500000>;
			etr-addr = <0x8f600000>;
			pageable-addr = <0x8f700000>;
			hremote-size = <0x1400000>;
			pageable-size = <0x700000>;
			tgt-mem-mode = <0x1>;
		#elif !defined(__IPQ_MEM_PROFILE_256_MB__)
			/* qcn9224 tgt-mem-mode=0 layout - 50MB
			 * +=========+==============+=========+
			 * |  Region | Start Offset |   Size  |
			 * +---------+--------------+---------+
			 * | HREMOTE |  0x8d900000  |   28MB  |
			 * +---------+--------------+---------+
			 * |  Caldb  |  0x8f500000  |   8MB   |
			 * +---------+--------------+---------+
			 * | M3 Dump |  0x8fd00000  |   1MB   |
			 * +---------+--------------+---------+
			 * |   ETR   |  0x8fe00000  |   1MB   |
			 * +---------+--------------+---------+
			 * |Pageable |  0x8ff00000  |  12MB   |
			 * +==================================+
			 */
			base-addr = <0x8d900000>;
			caldb-addr = <0x8f500000>;
			m3-dump-addr = <0x8fd00000>;
			etr-addr = <0x8fe00000>;
			pageable-addr = <0x8ff00000>;
			hremote-size = <0x1c00000>;
			pageable-size = <0xc00000>;
			tgt-mem-mode = <0x0>;
		#endif
			caldb-size = <0x800000>;
			qca,extended-intc;
			early_cal = <&pcie0>;
			interrupts-extended =
				<&qcn9224_in0 5 0>,
				<&qcn9224_in0 6 0>,
				<&qcn9224_in0 7 0>,
				<&qcn9224_in0 8 0>,
				<&qcn9224_in0 9 0>,
				<&qcn9224_in0 10 0>,
				<&qcn9224_in0 11 0>,
				<&qcn9224_in0 12 0>,
				<&qcn9224_in0 13 0>,
				<&qcn9224_in0 14 0>,
				<&qcn9224_in0 15 0>,
				<&qcn9224_in0 16 0>,
				<&qcn9224_in0 17 0>,
				<&qcn9224_in0 18 0>,
				<&qcn9224_in0 19 0>,
				<&qcn9224_in0 20 0>,
				<&qcn9224_in0 49 0>,
				<&qcn9224_in0 48 0>,
				<&qcn9224_in0 47 0>,
				<&qcn9224_in0 46 0>,
				<&qcn9224_in0 45 0>,
				<&qcn9224_in0 44 0>,
				<&qcn9224_in0 43 0>,
				<&qcn9224_in0 42 0>,
				<&qcn9224_in0 50 0>,
				<&qcn9224_in0 52 0>,
				<&qcn9224_in0 51 0>,
				<&qcn9224_in0 30 0>,
				<&qcn9224_in0 29 0>,
				<&qcn9224_in0 28 0>,
				<&qcn9224_in0 27 0>,
				<&qcn9224_in0 26 0>,
				<&qcn9224_in0 25 0>,
				<&qcn9224_in0 31 0>,
				<&qcn9224_in0 80 0>,
				<&qcn9224_in0 71 0>,
				<&qcn9224_in0 96 0>,
				<&qcn9224_in0 97 0>,
				<&qcn9224_in0 67 0>,
				<&qcn9224_in0 100 0>,
				<&qcn9224_in0 99 0>,
				<&qcn9224_in0 68 0>,
				<&qcn9224_in0 69 0>,
				<&qcn9224_in0 121 0>,
				<&qcn9224_in0 119 0>,
				<&qcn9224_in0 122 0>,
				<&qcn9224_in0 120 0>,
				<&qcn9224_in0 116 0>,
				<&qcn9224_in0 113 0>,
				<&qcn9224_in0 115 0>,
				<&qcn9224_in0 112 0>,
				<&qcn9224_in0 114 0>,
				<&qcn9224_in0 111 0>,
				<&qcn9224_in0 110 0>,
				<&qcn9224_in0 109 0>,
				<&qcn9224_in0 108 0>,
				<&qcn9224_in0 39 0>,
				<&qcn9224_in0 38 0>,
				<&qcn9224_in0 37 0>,
				<&qcn9224_in0 36 0>,
				<&qcn9224_in0 35 0>,
				<&qcn9224_in0 34 0>,
				<&qcn9224_in0 33 0>,
				<&qcn9224_in0 41 0>,
				<&qcn9224_in0 40 0>,
				<&qcn9224_in0 32 0>,
				<&qcn9224_in0 24 0>,
				<&qcn9224_in0 23 0>,
				<&qcn9224_in0 22 0>,
				<&qcn9224_in0 21 0>,
				<&qcn9224_in0 66 0>,
				<&qcn9224_in0 78 0>,
				<&qcn9224_in0 117 0>,
				<&qcn9224_in0 118 0>,
				<&qcn9224_in0 61 0>,
				<&qcn9224_in0 60 0>,
				<&qcn9224_in0 57 0>,
				<&qcn9224_in0 56 0>,
				<&qcn9224_in0 63 0>,
				<&qcn9224_in0 62 0>,
				<&qcn9224_in0 59 0>,
				<&qcn9224_in0 58 0>,
				<&qcn9224_in0 65 0>,
				<&qcn9224_in0 83 0>,
				<&qcn9224_in0 75 0>,
				<&qcn9224_in0 82 0>,
				<&qcn9224_in0 81 0>,
				<&qcn9224_in0 74 0>,
				<&qcn9224_in0 73 0>,
				<&qcn9224_in0 72 0>,
				<&qcn9224_in0 98 0>,
				<&qcn9224_in0 107 0>,
				<&qcn9224_in0 106 0>,
				<&qcn9224_in0 105 0>,
				<&qcn9224_in0 104 0>,
				<&qcn9224_in0 103 0>,
				<&qcn9224_in0 102 0>,
				<&qcn9224_in0 101 0>,
				<&qcn9224_in0 76 0>,
				<&qcn9224_in0 77 0>,
				<&qcn9224_in0 143 0>,
				<&qcn9224_in0 142 0>,
				<&qcn9224_in0 141 0>,
				<&intc GIC_SPI 75 IRQ_TYPE_LEVEL_HIGH>;

			interrupt-names = "ce0",
				"ce1",
				"ce2",
				"ce3",
				"ce4",
				"ce5",
				"ce6",
				"ce7",
				"ce8",
				"ce9",
				"ce10",
				"ce11",
				"ce12",
				"ce13",
				"ce14",
				"ce15",
				"reo2sw8_intr2",
				"reo2sw7_intr2",
				"reo2sw6_intr2",
				"reo2sw5_intr2",
				"reo2sw4_intr2",
				"reo2sw3_intr2",
				"reo2sw2_intr2",
				"reo2sw1_intr2",
				"reo2sw0_intr2",
				"reo2sw8_intr",
				"reo2sw7_intr",
				"reo2sw6_inrr",
				"reo2sw5_intr",
				"reo2sw4_intr",
				"reo2sw3_intr",
				"reo2sw2_intr",
				"reo2sw1_intr",
				"reo2sw0_intr",
				"reo2status_intr2",
				"reo_status",
				"reo2rxdma_out_2",
				"reo2rxdma_out_1",
				"reo_cmd",
				"sw2reo6",
				"sw2reo5",
				"sw2reo1",
				"sw2reo",
				"rxdma2reo_mlo_0_dst_ring1",
				"rxdma2reo_mlo_0_dst_ring0",
				"rxdma2reo_mlo_1_dst_ring1",
				"rxdma2reo_mlo_1_dst_ring0",
				"rxdma2reo_dst_ring1",
				"rxdma2reo_dst_ring0",
				"rxdma2sw_dst_ring1",
				"rxdma2sw_dst_ring0",
				"rxdma2release_dst_ring1",
				"rxdma2release_dst_ring0",
				"sw2rxdma_2_src_ring",
				"sw2rxdma_1_src_ring",
				"sw2rxdma_0",
				"wbm2sw6_release2",
				"wbm2sw5_release2",
				"wbm2sw4_release2",
				"wbm2sw3_release2",
				"wbm2sw2_release2",
				"wbm2sw1_release2",
				"wbm2sw0_release2",
				"wbm2sw6_release",
				"wbm2sw5_release",
				"wbm2sw4_release",
				"wbm2sw3_release",
				"wbm2sw2_release",
				"wbm2sw1_release",
				"wbm2sw0_release",
				"wbm2sw_link",
				"wbm_error_release",
				"sw2txmon_src_ring",
				"sw2rxmon_src_ring",
				"txmon2sw_p1_intr1",
				"txmon2sw_p1_intr0",
				"txmon2sw_p0_dest1",
				"txmon2sw_p0_dest0",
				"rxmon2sw_p1_intr1",
				"rxmon2sw_p1_intr0",
				"rxmon2sw_p0_dest1",
				"rxmon2sw_p0_dest0",
				"sw_release",
				"sw2tcl_credit2",
				"sw2tcl_credit",
				"sw2tcl4",
				"sw2tcl5",
				"sw2tcl3",
				"sw2tcl2",
				"sw2tcl1",
				"sw2wbm1",
				"misc_8",
				"misc_7",
				"misc_6",
				"misc_5",
				"misc_4",
				"misc_3",
				"misc_2",
				"misc_1",
				"misc_0",
				"mhi2",
				"mhi1",
				"mhi0",
				"inta";

			secure-reg = <0x00610408 0x130100>, /* pcie0 Main Ctl Low */
				     <0x00610438 0x44410>, /* pcie0 TrType LUT Low */
				     <0x00610448 0x100>, /* pci0 dynattr Alloc Low */
				     <0x00610450 0x6>; /* pci0 dynattr CacheIndexVal Low */
			status = "disabled";
		};

		wifi2: wifi2@f00000 {
			compatible  = "qcom,cnss-qcn9224";
		#ifdef __CONFIG_IO_COHERENCY__
			dma-coherent;
		#endif
			qcom,wlan-ramdump-dynamic = <0x600000>;
			qca,auto-restart;
			interrupt-bmap = <0x100512>;
			node_id = <1>;
		#ifdef __IPQ_MEM_PROFILE_512_MB__
			/* qcn9224 tgt-mem-mode=1 layout - 37MB
			 * +=========+==============+=========+
			 * |  Region | Start Offset |   Size  |
			 * +---------+--------------+---------+
			 * | HREMOTE |  0x8fe00000  |   20MB  |
			 * +---------+--------------+---------+
			 * |  Caldb  |  0x91200000  |   8MB   |
			 * +---------+--------------+---------+
			 * | M3 Dump |  0x91a00000  |   1MB   |
			 * +---------+--------------+---------+
			 * |   ETR   |  0x91b00000  |   1MB   |
			 * +---------+--------------+---------+
			 * |Pageable |  0x91c00000  |   7MB   |
			 * +==================================+
			 */
			base-addr = <0x8fe00000>;
			caldb-addr = <0x91200000>;
			m3-dump-addr = <0x91a00000>;
			etr-addr = <0x91b00000>;
			pageable-addr = <0x91c00000>;
			hremote-size = <0x1400000>;
			pageable-size = <0x700000>;
			tgt-mem-mode = <0x1>;
		#elif !defined(__IPQ_MEM_PROFILE_256_MB__)
			/* qcn9224 tgt-mem-mode=0 layout - 50MB
			 * +=========+==============+=========+
			 * |  Region | Start Offset |   Size  |
			 * +---------+--------------+---------+
			 * | HREMOTE |  0x90b00000  |   28MB  |
			 * +---------+--------------+---------+
			 * |  Caldb  |  0x92700000  |   8MB   |
			 * +---------+--------------+---------+
			 * | M3 Dump |  0x92f00000  |   1MB   |
			 * +---------+--------------+---------+
			 * |   ETR   |  0x93000000  |   1MB   |
			 * +---------+--------------+---------+
			 * |Pageable |  0x93100000  |  12MB   |
			 * +==================================+
			 */
			base-addr = <0x90b00000>;
			caldb-addr = <0x92700000>;
			m3-dump-addr = <0x92f00000>;
			etr-addr = <0x93000000>;
			pageable-addr = <0x93100000>;
			hremote-size = <0x1c00000>;
			pageable-size = <0xc00000>;
			tgt-mem-mode = <0x0>;
		#endif
			caldb-size = <0x800000>;
			qca,extended-intc;
			early_cal = <&pcie1>;
			interrupts-extended =
				<&qcn9224_in1 5 0>,
				<&qcn9224_in1 6 0>,
				<&qcn9224_in1 7 0>,
				<&qcn9224_in1 8 0>,
				<&qcn9224_in1 9 0>,
				<&qcn9224_in1 10 0>,
				<&qcn9224_in1 11 0>,
				<&qcn9224_in1 12 0>,
				<&qcn9224_in1 13 0>,
				<&qcn9224_in1 14 0>,
				<&qcn9224_in1 15 0>,
				<&qcn9224_in1 16 0>,
				<&qcn9224_in1 17 0>,
				<&qcn9224_in1 18 0>,
				<&qcn9224_in1 19 0>,
				<&qcn9224_in1 20 0>,
				<&qcn9224_in1 49 0>,
				<&qcn9224_in1 48 0>,
				<&qcn9224_in1 47 0>,
				<&qcn9224_in1 46 0>,
				<&qcn9224_in1 45 0>,
				<&qcn9224_in1 44 0>,
				<&qcn9224_in1 43 0>,
				<&qcn9224_in1 42 0>,
				<&qcn9224_in1 50 0>,
				<&qcn9224_in1 52 0>,
				<&qcn9224_in1 51 0>,
				<&qcn9224_in1 30 0>,
				<&qcn9224_in1 29 0>,
				<&qcn9224_in1 28 0>,
				<&qcn9224_in1 27 0>,
				<&qcn9224_in1 26 0>,
				<&qcn9224_in1 25 0>,
				<&qcn9224_in1 31 0>,
				<&qcn9224_in1 80 0>,
				<&qcn9224_in1 71 0>,
				<&qcn9224_in1 96 0>,
				<&qcn9224_in1 97 0>,
				<&qcn9224_in1 67 0>,
				<&qcn9224_in1 100 0>,
				<&qcn9224_in1 99 0>,
				<&qcn9224_in1 68 0>,
				<&qcn9224_in1 69 0>,
				<&qcn9224_in1 121 0>,
				<&qcn9224_in1 119 0>,
				<&qcn9224_in1 122 0>,
				<&qcn9224_in1 120 0>,
				<&qcn9224_in1 116 0>,
				<&qcn9224_in1 113 0>,
				<&qcn9224_in1 115 0>,
				<&qcn9224_in1 112 0>,
				<&qcn9224_in1 114 0>,
				<&qcn9224_in1 111 0>,
				<&qcn9224_in1 110 0>,
				<&qcn9224_in1 109 0>,
				<&qcn9224_in1 108 0>,
				<&qcn9224_in1 39 0>,
				<&qcn9224_in1 38 0>,
				<&qcn9224_in1 37 0>,
				<&qcn9224_in1 36 0>,
				<&qcn9224_in1 35 0>,
				<&qcn9224_in1 34 0>,
				<&qcn9224_in1 33 0>,
				<&qcn9224_in1 41 0>,
				<&qcn9224_in1 40 0>,
				<&qcn9224_in1 32 0>,
				<&qcn9224_in1 24 0>,
				<&qcn9224_in1 23 0>,
				<&qcn9224_in1 22 0>,
				<&qcn9224_in1 21 0>,
				<&qcn9224_in1 66 0>,
				<&qcn9224_in1 78 0>,
				<&qcn9224_in1 117 0>,
				<&qcn9224_in1 118 0>,
				<&qcn9224_in1 61 0>,
				<&qcn9224_in1 60 0>,
				<&qcn9224_in1 57 0>,
				<&qcn9224_in1 56 0>,
				<&qcn9224_in1 63 0>,
				<&qcn9224_in1 62 0>,
				<&qcn9224_in1 59 0>,
				<&qcn9224_in1 58 0>,
				<&qcn9224_in1 65 0>,
				<&qcn9224_in1 83 0>,
				<&qcn9224_in1 75 0>,
				<&qcn9224_in1 82 0>,
				<&qcn9224_in1 81 0>,
				<&qcn9224_in1 74 0>,
				<&qcn9224_in1 73 0>,
				<&qcn9224_in1 72 0>,
				<&qcn9224_in1 98 0>,
				<&qcn9224_in1 107 0>,
				<&qcn9224_in1 106 0>,
				<&qcn9224_in1 105 0>,
				<&qcn9224_in1 104 0>,
				<&qcn9224_in1 103 0>,
				<&qcn9224_in1 102 0>,
				<&qcn9224_in1 101 0>,
				<&qcn9224_in1 76 0>,
				<&qcn9224_in1 77 0>,
				<&qcn9224_in1 143 0>,
				<&qcn9224_in1 142 0>,
				<&qcn9224_in1 141 0>,
				<&intc GIC_SPI 35 IRQ_TYPE_LEVEL_HIGH>;

			interrupt-names = "ce0",
				"ce1",
				"ce2",
				"ce3",
				"ce4",
				"ce5",
				"ce6",
				"ce7",
				"ce8",
				"ce9",
				"ce10",
				"ce11",
				"ce12",
				"ce13",
				"ce14",
				"ce15",
				"reo2sw8_intr2",
				"reo2sw7_intr2",
				"reo2sw6_intr2",
				"reo2sw5_intr2",
				"reo2sw4_intr2",
				"reo2sw3_intr2",
				"reo2sw2_intr2",
				"reo2sw1_intr2",
				"reo2sw0_intr2",
				"reo2sw8_intr",
				"reo2sw7_intr",
				"reo2sw6_inrr",
				"reo2sw5_intr",
				"reo2sw4_intr",
				"reo2sw3_intr",
				"reo2sw2_intr",
				"reo2sw1_intr",
				"reo2sw0_intr",
				"reo2status_intr2",
				"reo_status",
				"reo2rxdma_out_2",
				"reo2rxdma_out_1",
				"reo_cmd",
				"sw2reo6",
				"sw2reo5",
				"sw2reo1",
				"sw2reo",
				"rxdma2reo_mlo_0_dst_ring1",
				"rxdma2reo_mlo_0_dst_ring0",
				"rxdma2reo_mlo_1_dst_ring1",
				"rxdma2reo_mlo_1_dst_ring0",
				"rxdma2reo_dst_ring1",
				"rxdma2reo_dst_ring0",
				"rxdma2sw_dst_ring1",
				"rxdma2sw_dst_ring0",
				"rxdma2release_dst_ring1",
				"rxdma2release_dst_ring0",
				"sw2rxdma_2_src_ring",
				"sw2rxdma_1_src_ring",
				"sw2rxdma_0",
				"wbm2sw6_release2",
				"wbm2sw5_release2",
				"wbm2sw4_release2",
				"wbm2sw3_release2",
				"wbm2sw2_release2",
				"wbm2sw1_release2",
				"wbm2sw0_release2",
				"wbm2sw6_release",
				"wbm2sw5_release",
				"wbm2sw4_release",
				"wbm2sw3_release",
				"wbm2sw2_release",
				"wbm2sw1_release",
				"wbm2sw0_release",
				"wbm2sw_link",
				"wbm_error_release",
				"sw2txmon_src_ring",
				"sw2rxmon_src_ring",
				"txmon2sw_p1_intr1",
				"txmon2sw_p1_intr0",
				"txmon2sw_p0_dest1",
				"txmon2sw_p0_dest0",
				"rxmon2sw_p1_intr1",
				"rxmon2sw_p1_intr0",
				"rxmon2sw_p0_dest1",
				"rxmon2sw_p0_dest0",
				"sw_release",
				"sw2tcl_credit2",
				"sw2tcl_credit",
				"sw2tcl4",
				"sw2tcl5",
				"sw2tcl3",
				"sw2tcl2",
				"sw2tcl1",
				"sw2wbm1",
				"misc_8",
				"misc_7",
				"misc_6",
				"misc_5",
				"misc_4",
				"misc_3",
				"misc_2",
				"misc_1",
				"misc_0",
				"mhi2",
				"mhi1",
				"mhi0",
				"inta";

			secure-reg = <0x00610508 0x130100>, /* pcie1 Main Ctl Low */
				     <0x00610538 0x44410>, /* pcie1 TrType LUT Low */
				     <0x00610548 0x100>, /* pci1 dynattr Alloc Low */
				     <0x00610550 0x7>; /* pci1 dynattr CacheIndexVal Low */
			status = "disabled";
		};

		wifi3: wifi3@f00000 {
			compatible  = "qcom,cnss-qcn9224";
		#ifdef __CONFIG_IO_COHERENCY__
			dma-coherent;
		#endif
			qcom,wlan-ramdump-dynamic = <0x600000>;
			qca,auto-restart;
			interrupt-bmap = <0x100512>;
			node_id = <2>;
		#ifdef __IPQ_MEM_PROFILE_512_MB__
			/* qcn9224 tgt-mem-mode=1 layout - 37MB
			 * +=========+==============+=========+
			 * |  Region | Start Offset |   Size  |
			 * +---------+--------------+---------+
			 * | HREMOTE |  0x92300000  |   20MB  |
			 * +---------+--------------+---------+
			 * |  Caldb  |  0x93700000  |   8MB   |
			 * +---------+--------------+---------+
			 * | M3 Dump |  0x93f00000  |   1MB   |
			 * +---------+--------------+---------+
			 * |   ETR   |  0x94000000  |   1MB   |
			 * +---------+--------------+---------+
			 * |Pageable |  0x94100000  |   7MB   |
			 * +==================================+
			 */
			base-addr = <0x92300000>;
			caldb-addr = <0x93700000>;
			m3-dump-addr = <0x93f00000>;
			etr-addr = <0x94000000>;
			pageable-addr = <0x94100000>;
			hremote-size = <0x1400000>;
			pageable-size = <0x700000>;
			tgt-mem-mode = <0x1>;
		#elif !defined(__IPQ_MEM_PROFILE_256_MB__)
			/* qcn9224 tgt-mem-mode=0 layout - 50MB
			 * +=========+==============+=========+
			 * |  Region | Start Offset |   Size  |
			 * +---------+--------------+---------+
			 * | HREMOTE |  0x93d00000  |   28MB  |
			 * +---------+--------------+---------+
			 * |  Caldb  |  0x95900000  |   8MB   |
			 * +---------+--------------+---------+
			 * | M3 Dump |  0x96100000  |   1MB   |
			 * +---------+--------------+---------+
			 * |   ETR   |  0x96200000  |   1MB   |
			 * +---------+--------------+---------+
			 * |Pageable |  0x96300000  |  12MB   |
			 * +==================================+
			 */
			base-addr = <0x93d00000>;
			caldb-addr = <0x95900000>;
			m3-dump-addr = <0x96100000>;
			etr-addr = <0x96200000>;
			pageable-addr = <0x96300000>;
			hremote-size = <0x1c00000>;
			pageable-size = <0xc00000>;
			tgt-mem-mode = <0x0>;
		#endif
			caldb-size = <0x800000>;
			qca,extended-intc;
			early_cal = <&pcie2>;
			interrupts-extended =
				<&qcn9224_in2 5 0>,
				<&qcn9224_in2 6 0>,
				<&qcn9224_in2 7 0>,
				<&qcn9224_in2 8 0>,
				<&qcn9224_in2 9 0>,
				<&qcn9224_in2 10 0>,
				<&qcn9224_in2 11 0>,
				<&qcn9224_in2 12 0>,
				<&qcn9224_in2 13 0>,
				<&qcn9224_in2 14 0>,
				<&qcn9224_in2 15 0>,
				<&qcn9224_in2 16 0>,
				<&qcn9224_in2 17 0>,
				<&qcn9224_in2 18 0>,
				<&qcn9224_in2 19 0>,
				<&qcn9224_in2 20 0>,
				<&qcn9224_in2 49 0>,
				<&qcn9224_in2 48 0>,
				<&qcn9224_in2 47 0>,
				<&qcn9224_in2 46 0>,
				<&qcn9224_in2 45 0>,
				<&qcn9224_in2 44 0>,
				<&qcn9224_in2 43 0>,
				<&qcn9224_in2 42 0>,
				<&qcn9224_in2 50 0>,
				<&qcn9224_in2 52 0>,
				<&qcn9224_in2 51 0>,
				<&qcn9224_in2 30 0>,
				<&qcn9224_in2 29 0>,
				<&qcn9224_in2 28 0>,
				<&qcn9224_in2 27 0>,
				<&qcn9224_in2 26 0>,
				<&qcn9224_in2 25 0>,
				<&qcn9224_in2 31 0>,
				<&qcn9224_in2 80 0>,
				<&qcn9224_in2 71 0>,
				<&qcn9224_in2 96 0>,
				<&qcn9224_in2 97 0>,
				<&qcn9224_in2 67 0>,
				<&qcn9224_in2 100 0>,
				<&qcn9224_in2 99 0>,
				<&qcn9224_in2 68 0>,
				<&qcn9224_in2 69 0>,
				<&qcn9224_in2 121 0>,
				<&qcn9224_in2 119 0>,
				<&qcn9224_in2 122 0>,
				<&qcn9224_in2 120 0>,
				<&qcn9224_in2 116 0>,
				<&qcn9224_in2 113 0>,
				<&qcn9224_in2 115 0>,
				<&qcn9224_in2 112 0>,
				<&qcn9224_in2 114 0>,
				<&qcn9224_in2 111 0>,
				<&qcn9224_in2 110 0>,
				<&qcn9224_in2 109 0>,
				<&qcn9224_in2 108 0>,
				<&qcn9224_in2 39 0>,
				<&qcn9224_in2 38 0>,
				<&qcn9224_in2 37 0>,
				<&qcn9224_in2 36 0>,
				<&qcn9224_in2 35 0>,
				<&qcn9224_in2 34 0>,
				<&qcn9224_in2 33 0>,
				<&qcn9224_in2 41 0>,
				<&qcn9224_in2 40 0>,
				<&qcn9224_in2 32 0>,
				<&qcn9224_in2 24 0>,
				<&qcn9224_in2 23 0>,
				<&qcn9224_in2 22 0>,
				<&qcn9224_in2 21 0>,
				<&qcn9224_in2 66 0>,
				<&qcn9224_in2 78 0>,
				<&qcn9224_in2 117 0>,
				<&qcn9224_in2 118 0>,
				<&qcn9224_in2 61 0>,
				<&qcn9224_in2 60 0>,
				<&qcn9224_in2 57 0>,
				<&qcn9224_in2 56 0>,
				<&qcn9224_in2 63 0>,
				<&qcn9224_in2 62 0>,
				<&qcn9224_in2 59 0>,
				<&qcn9224_in2 58 0>,
				<&qcn9224_in2 65 0>,
				<&qcn9224_in2 83 0>,
				<&qcn9224_in2 75 0>,
				<&qcn9224_in2 82 0>,
				<&qcn9224_in2 81 0>,
				<&qcn9224_in2 74 0>,
				<&qcn9224_in2 73 0>,
				<&qcn9224_in2 72 0>,
				<&qcn9224_in2 98 0>,
				<&qcn9224_in2 107 0>,
				<&qcn9224_in2 106 0>,
				<&qcn9224_in2 105 0>,
				<&qcn9224_in2 104 0>,
				<&qcn9224_in2 103 0>,
				<&qcn9224_in2 102 0>,
				<&qcn9224_in2 101 0>,
				<&qcn9224_in2 76 0>,
				<&qcn9224_in2 77 0>,
				<&qcn9224_in2 143 0>,
				<&qcn9224_in2 142 0>,
				<&qcn9224_in2 141 0>,
				<&intc GIC_SPI 164 IRQ_TYPE_LEVEL_HIGH>;

			interrupt-names = "ce0",
				"ce1",
				"ce2",
				"ce3",
				"ce4",
				"ce5",
				"ce6",
				"ce7",
				"ce8",
				"ce9",
				"ce10",
				"ce11",
				"ce12",
				"ce13",
				"ce14",
				"ce15",
				"reo2sw8_intr2",
				"reo2sw7_intr2",
				"reo2sw6_intr2",
				"reo2sw5_intr2",
				"reo2sw4_intr2",
				"reo2sw3_intr2",
				"reo2sw2_intr2",
				"reo2sw1_intr2",
				"reo2sw0_intr2",
				"reo2sw8_intr",
				"reo2sw7_intr",
				"reo2sw6_inrr",
				"reo2sw5_intr",
				"reo2sw4_intr",
				"reo2sw3_intr",
				"reo2sw2_intr",
				"reo2sw1_intr",
				"reo2sw0_intr",
				"reo2status_intr2",
				"reo_status",
				"reo2rxdma_out_2",
				"reo2rxdma_out_1",
				"reo_cmd",
				"sw2reo6",
				"sw2reo5",
				"sw2reo1",
				"sw2reo",
				"rxdma2reo_mlo_0_dst_ring1",
				"rxdma2reo_mlo_0_dst_ring0",
				"rxdma2reo_mlo_1_dst_ring1",
				"rxdma2reo_mlo_1_dst_ring0",
				"rxdma2reo_dst_ring1",
				"rxdma2reo_dst_ring0",
				"rxdma2sw_dst_ring1",
				"rxdma2sw_dst_ring0",
				"rxdma2release_dst_ring1",
				"rxdma2release_dst_ring0",
				"sw2rxdma_2_src_ring",
				"sw2rxdma_1_src_ring",
				"sw2rxdma_0",
				"wbm2sw6_release2",
				"wbm2sw5_release2",
				"wbm2sw4_release2",
				"wbm2sw3_release2",
				"wbm2sw2_release2",
				"wbm2sw1_release2",
				"wbm2sw0_release2",
				"wbm2sw6_release",
				"wbm2sw5_release",
				"wbm2sw4_release",
				"wbm2sw3_release",
				"wbm2sw2_release",
				"wbm2sw1_release",
				"wbm2sw0_release",
				"wbm2sw_link",
				"wbm_error_release",
				"sw2txmon_src_ring",
				"sw2rxmon_src_ring",
				"txmon2sw_p1_intr1",
				"txmon2sw_p1_intr0",
				"txmon2sw_p0_dest1",
				"txmon2sw_p0_dest0",
				"rxmon2sw_p1_intr1",
				"rxmon2sw_p1_intr0",
				"rxmon2sw_p0_dest1",
				"rxmon2sw_p0_dest0",
				"sw_release",
				"sw2tcl_credit2",
				"sw2tcl_credit",
				"sw2tcl4",
				"sw2tcl5",
				"sw2tcl3",
				"sw2tcl2",
				"sw2tcl1",
				"sw2wbm1",
				"misc_8",
				"misc_7",
				"misc_6",
				"misc_5",
				"misc_4",
				"misc_3",
				"misc_2",
				"misc_1",
				"misc_0",
				"mhi2",
				"mhi1",
				"mhi0",
				"inta";

			secure-reg = <0x00610608 0x130100>, /* pcie2 Main Ctl Low */
				     <0x00610638 0x44410>, /* pcie2 TrType LUT Low */
				     <0x00610648 0x100>, /* pci2 dynattr Alloc Low */
				     <0x00610650 0x6>; /* pci2 dynattr CacheIndexVal Low */
			status = "disabled";
		};

		wifi4: wifi4@f00000 {
			compatible  = "qcom,cnss-qcn9224";
		#ifdef __CONFIG_IO_COHERENCY__
			dma-coherent;
		#endif
			qcom,wlan-ramdump-dynamic = <0x600000>;
			qca,auto-restart;
			interrupt-bmap = <0x100512>;
			node_id = <3>;
		#ifdef __IPQ_MEM_PROFILE_512_MB__
			/* qcn9224 tgt-mem-mode=1 layout - 50MB
			 * +=========+==============+=========+
			 * |  Region | Start Offset |   Size  |
			 * +---------+--------------+---------+
			 * | HREMOTE |  0x94800000  |   20MB  |
			 * +---------+--------------+---------+
			 * |  Caldb  |  0x95c00000  |   8MB   |
			 * +---------+--------------+---------+
			 * | M3 Dump |  0x96400000  |   1MB   |
			 * +---------+--------------+---------+
			 * |   ETR   |  0x96500000  |   1MB   |
			 * +---------+--------------+---------+
			 * |Pageable |  0x96600000  |   7MB   |
			 * +==================================+
			 */
			base-addr = <0x94800000>;
			caldb-addr = <0x95c00000>;
			m3-dump-addr = <0x96400000>;
			etr-addr = <0x96500000>;
			pageable-addr = <0x96600000>;
			hremote-size = <0x1400000>;
			pageable-size = <0x700000>;
			tgt-mem-mode = <0x1>;
		#elif !defined(__IPQ_MEM_PROFILE_256_MB__)
			/* qcn9224 tgt-mem-mode=0 layout - 50MB
			 * +=========+==============+=========+
			 * |  Region | Start Offset |   Size  |
			 * +---------+--------------+---------+
			 * | HREMOTE |  0x96f00000  |   28MB  |
			 * +---------+--------------+---------+
			 * |  Caldb  |  0x98b00000  |   8MB   |
			 * +---------+--------------+---------+
			 * | M3 Dump |  0x99300000  |   1MB   |
			 * +---------+--------------+---------+
			 * |   ETR   |  0x99400000  |   1MB   |
			 * +---------+--------------+---------+
			 * |Pageable |  0x99500000  |  12MB   |
			 * +==================================+
			 */
			base-addr = <0x96f00000>;
			caldb-addr = <0x98b00000>;
			m3-dump-addr = <0x99300000>;
			etr-addr = <0x99400000>;
			pageable-addr = <0x99500000>;
			hremote-size = <0x1c00000>;
			pageable-size = <0xc00000>;
			tgt-mem-mode = <0x0>;
		#endif
			caldb-size = <0x800000>;
			qca,extended-intc;
			early_cal = <&pcie3>;
			interrupts-extended =
				<&qcn9224_in3 5 0>,
				<&qcn9224_in3 6 0>,
				<&qcn9224_in3 7 0>,
				<&qcn9224_in3 8 0>,
				<&qcn9224_in3 9 0>,
				<&qcn9224_in3 10 0>,
				<&qcn9224_in3 11 0>,
				<&qcn9224_in3 12 0>,
				<&qcn9224_in3 13 0>,
				<&qcn9224_in3 14 0>,
				<&qcn9224_in3 15 0>,
				<&qcn9224_in3 16 0>,
				<&qcn9224_in3 17 0>,
				<&qcn9224_in3 18 0>,
				<&qcn9224_in3 19 0>,
				<&qcn9224_in3 20 0>,
				<&qcn9224_in3 49 0>,
				<&qcn9224_in3 48 0>,
				<&qcn9224_in3 47 0>,
				<&qcn9224_in3 46 0>,
				<&qcn9224_in3 45 0>,
				<&qcn9224_in3 44 0>,
				<&qcn9224_in3 43 0>,
				<&qcn9224_in3 42 0>,
				<&qcn9224_in3 50 0>,
				<&qcn9224_in3 52 0>,
				<&qcn9224_in3 51 0>,
				<&qcn9224_in3 30 0>,
				<&qcn9224_in3 29 0>,
				<&qcn9224_in3 28 0>,
				<&qcn9224_in3 27 0>,
				<&qcn9224_in3 26 0>,
				<&qcn9224_in3 25 0>,
				<&qcn9224_in3 31 0>,
				<&qcn9224_in3 80 0>,
				<&qcn9224_in3 71 0>,
				<&qcn9224_in3 96 0>,
				<&qcn9224_in3 97 0>,
				<&qcn9224_in3 67 0>,
				<&qcn9224_in3 100 0>,
				<&qcn9224_in3 99 0>,
				<&qcn9224_in3 68 0>,
				<&qcn9224_in3 69 0>,
				<&qcn9224_in3 121 0>,
				<&qcn9224_in3 119 0>,
				<&qcn9224_in3 122 0>,
				<&qcn9224_in3 120 0>,
				<&qcn9224_in3 116 0>,
				<&qcn9224_in3 113 0>,
				<&qcn9224_in3 115 0>,
				<&qcn9224_in3 112 0>,
				<&qcn9224_in3 114 0>,
				<&qcn9224_in3 111 0>,
				<&qcn9224_in3 110 0>,
				<&qcn9224_in3 109 0>,
				<&qcn9224_in3 108 0>,
				<&qcn9224_in3 39 0>,
				<&qcn9224_in3 38 0>,
				<&qcn9224_in3 37 0>,
				<&qcn9224_in3 36 0>,
				<&qcn9224_in3 35 0>,
				<&qcn9224_in3 34 0>,
				<&qcn9224_in3 33 0>,
				<&qcn9224_in3 41 0>,
				<&qcn9224_in3 40 0>,
				<&qcn9224_in3 32 0>,
				<&qcn9224_in3 24 0>,
				<&qcn9224_in3 23 0>,
				<&qcn9224_in3 22 0>,
				<&qcn9224_in3 21 0>,
				<&qcn9224_in3 66 0>,
				<&qcn9224_in3 78 0>,
				<&qcn9224_in3 117 0>,
				<&qcn9224_in3 118 0>,
				<&qcn9224_in3 61 0>,
				<&qcn9224_in3 60 0>,
				<&qcn9224_in3 57 0>,
				<&qcn9224_in3 56 0>,
				<&qcn9224_in3 63 0>,
				<&qcn9224_in3 62 0>,
				<&qcn9224_in3 59 0>,
				<&qcn9224_in3 58 0>,
				<&qcn9224_in3 65 0>,
				<&qcn9224_in3 83 0>,
				<&qcn9224_in3 75 0>,
				<&qcn9224_in3 82 0>,
				<&qcn9224_in3 81 0>,
				<&qcn9224_in3 74 0>,
				<&qcn9224_in3 73 0>,
				<&qcn9224_in3 72 0>,
				<&qcn9224_in3 98 0>,
				<&qcn9224_in3 107 0>,
				<&qcn9224_in3 106 0>,
				<&qcn9224_in3 105 0>,
				<&qcn9224_in3 104 0>,
				<&qcn9224_in3 103 0>,
				<&qcn9224_in3 102 0>,
				<&qcn9224_in3 101 0>,
				<&qcn9224_in3 76 0>,
				<&qcn9224_in3 77 0>,
				<&qcn9224_in3 143 0>,
				<&qcn9224_in3 142 0>,
				<&qcn9224_in3 141 0>,
				<&intc GIC_SPI 189 IRQ_TYPE_LEVEL_HIGH>;

			interrupt-names = "ce0",
				"ce1",
				"ce2",
				"ce3",
				"ce4",
				"ce5",
				"ce6",
				"ce7",
				"ce8",
				"ce9",
				"ce10",
				"ce11",
				"ce12",
				"ce13",
				"ce14",
				"ce15",
				"reo2sw8_intr2",
				"reo2sw7_intr2",
				"reo2sw6_intr2",
				"reo2sw5_intr2",
				"reo2sw4_intr2",
				"reo2sw3_intr2",
				"reo2sw2_intr2",
				"reo2sw1_intr2",
				"reo2sw0_intr2",
				"reo2sw8_intr",
				"reo2sw7_intr",
				"reo2sw6_inrr",
				"reo2sw5_intr",
				"reo2sw4_intr",
				"reo2sw3_intr",
				"reor",
				"reo2sw1_intr",
				"reo2sw0_intr",
				"reo2status_intr2",
				"reo_status",
				"reo2rxdma_out_2",
				"reo2rxdma_out_1",
				"reo_cmd",
				"sw2reo6",
				"sw2reo5",
				"sw2reo1",
				"sw2reo",
				"rxdma2reo_mlo_0_dst_ring1",
				"rxdma2reo_mlo_0_dst_ring0",
				"rxdma2reo_mlo_1_dst_ring1",
				"rxdma2reo_mlo_1_dst_ring0",
				"rxdma2reo_dst_ring1",
				"rxdma2reo_dst_ring0",
				"rxdma2sw_dst_ring1",
				"rxdma2sw_dst_ring0",
				"rxdma2release_dst_ring1",
				"rxdma2release_dst_ring0",
				"sw2rxdma_2_src_ring",
				"sw2rxdma_1_src_ring",
				"sw2rxdma_0",
				"wbm2sw6_release2",
				"wbm2sw5_release2",
				"wbm2sw4_release2",
				"wbm2sw3_release2",
				"wbm2sw2_release2",
				"wbm2sw1_release2",
				"wbm2sw0_release2",
				"wbm2sw6_release",
				"wbm2sw5_release",
				"wbm2sw4_release",
				"wbm2sw3_release",
				"wbm2sw2_release",
				"wbm2sw1_release",
				"wbm2sw0_release",
				"wbm2sw_link",
				"wbm_error_release",
				"sw2txmon_src_ring",
				"sw2rxmon_src_ring",
				"txmon2sw_p1_intr1",
				"txmon2sw_p1_intr0",
				"txmon2sw_p0_dest1",
				"txmon2sw_p0_dest0",
				"rxmon2sw_p1_intr1",
				"rxmon2sw_p1_intr0",
				"rxmon2sw_p0_dest1",
				"rxmon2sw_p0_dest0",
				"sw_release",
				"sw2tcl_credit2",
				"sw2tcl_credit",
				"sw2tcl4",
				"sw2tcl5",
				"sw2tcl3",
				"sw2tcl2",
				"sw2tcl1",
				"sw2wbm1",
				"misc_8",
				"misc_7",
				"misc_6",
				"misc_5",
				"misc_4",
				"misc_3",
				"misc_2",
				"misc_1",
				"misc_0",
				"mhi2",
				"mhi1",
				"mhi0",
				"inta";

			secure-reg = <0x00610708 0x130100>, /* pcie3 Main Ctl Low */
				     <0x00610738 0x44410>, /* pcie3 TrType LUT Low */
				     <0x00610748 0x100>, /* pci3 dynattr Alloc Low */
				     <0x00610750 0x7>; /* pci3 dynattr CacheIndexVal Low */
			status = "disabled";
		};

		stm: stm@6002000 {
			compatible = "arm,coresight-stm", "arm,primecell";
			reg = <0x06002000 0x1000>,
				<0x09000000 0x01000000>;
			reg-names = "stm-base", "stm-stimulus-base";
			coresight-name = "coresight-stm";
			clocks = <&gcc GCC_QDSS_DAP_CLK>,
				 <&gcc GCC_QDSS_AT_CLK>;
			clock-names = "apb_pclk", "atclk";

			out-ports {
				port {
					stm_out: endpoint {
						remote-endpoint = <&funnel0_in7>;
					};
				};
			};
		};

		funnel_in0: funnel@6041000 {
			compatible = "arm,coresight-dynamic-funnel", "arm,primecell";
			reg = <0x6041000 0x1000>;
			reg-names = "funnel-base";
			coresight-name = "coresight-funnel-in0";
			clocks = <&gcc GCC_QDSS_DAP_CLK>,
				 <&gcc GCC_QDSS_AT_CLK>;
			clock-names = "apb_pclk", "atclk";

			in-ports {
				#address-cells = <1>;
				#size-cells = <0>;

				/*
				 * Port 0 - TME
				 * Port 2 - SNOC
				 * Port 3 - NSS
				 * Port 4 - CNOC
				 * Port 5 - MEMNOC
				 * Port 6 - TPDA QDSS
				 */

				port@7 {
					reg = <7>;
					funnel0_in7: endpoint {
						remote-endpoint = <&stm_out>;
					};
				};
			};

			out-ports {
				port {
					funnel0_out: endpoint {
						remote-endpoint = <&merge_funnel_in0>;
					};
				};
			};
		};

		funnel_qatb: funnel@640f000 {
			compatible = "arm,coresight-dynamic-funnel", "arm,primecell";
			reg = <0x0640f000 0x1000>;
			reg-names = "funnel-base";
			coresight-name = "coresight-qatb-in";
			clocks = <&gcc GCC_QDSS_DAP_CLK>,
				 <&gcc GCC_QDSS_AT_CLK>;
			clock-names = "apb_pclk", "atclk";

			in-ports {
				#address-cells = <1>;
				#size-cells = <0>;

				/*
				 * Port 0 - TPDA
				 */

				port@0 {
					reg = <0>;
					llcc_qatb_in0: endpoint {
						remote-endpoint = <&tpda_qdss_out>;
					};
				};
			};

			out-ports {
				port {
					qatb_out: endpoint {
						remote-endpoint = <&funnel1_in3>;
					};
				};
			};

		};



		funnel_in1: funnel@6042000 {
			compatible = "arm,coresight-dynamic-funnel", "arm,primecell";
			reg = <0x06042000 0x1000>;
			reg-names = "funnel-base";
			coresight-name = "coresight-funnel-in1";
			clocks = <&gcc GCC_QDSS_DAP_CLK>,
				 <&gcc GCC_QDSS_AT_CLK>;
			clock-names = "apb_pclk", "atclk";

			in-ports {
				#address-cells = <1>;
				#size-cells = <0>;

				/*
				 * Port 0 - AGGRENOC
				 * Port 1 - WCSS Q6
				 * Port 3 - TPDA QDSS
				 * Port 5 - WCSS Core
				 */

				port@2 {
					reg = <4>;
					funnel1_in2: endpoint {
						remote-endpoint = <&apss_funnel_out>;
					};
				};
				port@3 {
					reg = <3>;
					funnel1_in3: endpoint {
						remote-endpoint = <&qatb_out>;
					};
				};
			};

			out-ports {
				port {
					funnel1_out: endpoint {
						remote-endpoint = <&merge_funnel_in1>;
					};
				};
			};

		};

		funnel_merge: funnel@6045000 {
			compatible = "arm,coresight-dynamic-funnel", "arm,primecell";
			reg = <0x06045000 0x1000>;
			reg-names = "funnel-base";
			coresight-name = "coresight-funnel-merge";
			clocks = <&gcc GCC_QDSS_DAP_CLK>,
				 <&gcc GCC_QDSS_AT_CLK>;
			clock-names = "apb_pclk", "atclk";

			out-ports {
				port {
					merge_funnel_out: endpoint {
						remote-endpoint = <&etf_in>;
					};
				};
			};

			in-ports {
				#address-cells = <1>;
				#size-cells = <0>;

				port@0 {
					reg = <0>;
					merge_funnel_in0: endpoint {
						remote-endpoint = <&funnel0_out>;
					};
				};

				port@1 {
					reg = <1>;
					merge_funnel_in1: endpoint {
						remote-endpoint = <&funnel1_out>;
					};
				};
			};

		};

		etr_replicator: replicator@6046000 {
			compatible = "arm,coresight-dynamic-replicator", "arm,primecell";
			reg = <0x06046000 0x1000>;
			reg-names = "replicator-base";
			coresight-name = "coresight-replicator";
			clocks = <&gcc GCC_QDSS_DAP_CLK>,
				 <&gcc GCC_QDSS_AT_CLK>;
			clock-names = "apb_pclk", "atclk";

			out-ports {
				#address-cells = <1>;
				#size-cells = <0>;

				port@0 {
					reg = <0>;
					etr_replicator_out0: endpoint {
						remote-endpoint = <&etr_in>;
					};
				};
			};

			in-ports {
				port {
					etr_replicator_in0: endpoint {
						remote-endpoint = <&etf_out>;
					};
				};
			};
		};

		etf@6047000 {
			compatible = "arm,coresight-tmc", "arm,primecell";
			reg = <0x06047000 0x1000>;
			reg-names = "tmc-base";
			coresight-name = "coresight-tmc-etf";
			arm,default-sink;
			clocks = <&gcc GCC_QDSS_DAP_CLK>;
			clock-names = "apb_pclk";

			out-ports {
				port {
					etf_out: endpoint {
						remote-endpoint = <&etr_replicator_in0>;
					};
				};
			};

			in-ports {
				port {
					etf_in: endpoint {
						remote-endpoint = <&merge_funnel_out>;
					};
				};
			};
		};

		tmc_etr: tmc@6048000 {
			compatible = "arm,coresight-tmc", "arm,primecell";
			reg = <0x06048000 0x1000>;
			reg-names = "tmc-base";
			interrupts = <GIC_SPI 166 IRQ_TYPE_EDGE_RISING>;
			interrupt-names = "byte-cntr-irq";
			arm,buffer-size = <0x100000>;
			arm,scatter-gather;
			memory-region = <&tmc_etr_region>;
			coresight-name = "coresight-tmc-etr";
			clocks = <&gcc GCC_QDSS_DAP_CLK>;
			clock-names = "apb_pclk";

			in-ports {
				port {
					etr_in: endpoint {
						remote-endpoint = <&etr_replicator_out0>;
					};
				};
			};
		};

		etm0: etm@6480000 {
			compatible = "arm,coresight-etm4x", "arm,primecell";
			reg = <0x6480000 0x1000>;
			coresight-name = "coresight-etm0";
			cpu = <&CPU0>;
			clocks = <&gcc GCC_QDSS_DAP_CLK>;
			clock-names = "apb_pclk";

			out-ports {
				port {
					etm0_out: endpoint {
						remote-endpoint = <&apss_funnel_in0>;
					};
				};
			};
		};

		etm1: etm@6580000 {
			compatible = "arm,coresight-etm4x", "arm,primecell";
			reg = <0x6580000 0x1000>;
			coresight-name = "coresight-etm1";
			cpu = <&CPU1>;
			clocks = <&gcc GCC_QDSS_DAP_CLK>;
			clock-names = "apb_pclk";

			out-ports {
				port {
					etm1_out: endpoint {
						remote-endpoint = <&apss_funnel_in1>;
					};
				};
			};
		};

		etm2: etm@6680000 {
			compatible = "arm,coresight-etm4x", "arm,primecell";
			reg = <0x6680000 0x1000>;
			coresight-name = "coresight-etm2";
			cpu = <&CPU2>;
			clocks = <&gcc GCC_QDSS_DAP_CLK>;
			clock-names = "apb_pclk";

			out-ports {
				port {
					etm2_out: endpoint {
						remote-endpoint = <&apss_funnel_in2>;
					};
				};
			};
		};

		etm3: etm@6780000 {
			compatible = "arm,coresight-etm4x", "arm,primecell";
			reg = <0x6780000 0x1000>;
			coresight-name = "coresight-etm3";
			cpu = <&CPU3>;
			clocks = <&gcc GCC_QDSS_DAP_CLK>;
			clock-names = "apb_pclk";

			out-ports {
				port {
					etm3_out: endpoint {
						remote-endpoint = <&apss_funnel_in3>;
					};
				};
			};
		};

		funnel_apss: funnel@6781000 {
			compatible = "arm,coresight-dynamic-funnel", "arm,primecell";
			reg = <0x6781000 0x1000>;
			reg-names = "funnel-base";
			coresight-name = "coresight-funnel-apss";
			clocks = <&gcc GCC_QDSS_DAP_CLK>,
				 <&gcc GCC_QDSS_AT_CLK>;
			clock-names = "apb_pclk", "atclk";

			out-ports {
				port {
					apss_funnel_out: endpoint {
						remote-endpoint = <&funnel1_in2>;
					};
				};
			};

			in-ports {
				#address-cells = <1>;
				#size-cells = <0>;

				port@0 {
					reg = <0>;
					apss_funnel_in0: endpoint {
						remote-endpoint = <&etm0_out>;
					};
				};

				port@1 {
					reg = <1>;
					apss_funnel_in1: endpoint {
						remote-endpoint = <&etm1_out>;
					};
				};

				port@2 {
					reg = <2>;
					apss_funnel_in2: endpoint {
						remote-endpoint = <&etm2_out>;
					};
				};

				port@3 {
					reg = <3>;
					apss_funnel_in3: endpoint {
						remote-endpoint = <&etm3_out>;
					};
				};
			};
		};

		tpdm@6408000 {
			compatible = "qcom,coresight-tpdm", "arm,primecell";
			reg = <0x6408000 0x1000>;
			coresight-name = "coresight-tpdm";
			clocks = <&gcc GCC_QDSS_DAP_CLK>,
				<&gcc GCC_QDSS_AT_CLK>;
			clock-names = "apb_pclk", "atclk";
			out-ports {
				port {
					llcc_tpdm_out: endpoint {
						remote-endpoint = <&tpda_in11>;
					};
				};
			};
		};

	       tpda@640e000 {
		       compatible = "qcom,coresight-tpda", "arm,primecell";
		       reg = <0x640e000 0x1000>;
		       coresight-name = "coresight-tpda";
		       clocks = <&gcc GCC_QDSS_DAP_CLK>,
			      <&gcc GCC_QDSS_AT_CLK>;

		       clock-names = "apb_pclk", "atclk";

		       in-ports {
				#address-cells = <1>;
				#size-cells = <0>;

			       port@11 {
				       reg = <11>;
					tpda_in11: endpoint {
						remote-endpoint = <&llcc_tpdm_out>;
					};
			      };
		       };
		       out-ports {
			       port {
					tpda_qdss_out: endpoint {
						remote-endpoint = <&llcc_qatb_in0>;
					};
			       };
		       };
	       };

		imem: sram@8600000 {
			compatible = "qcom,ipq5424-imem", "syscon", "simple-mfd";
			reg = <0x08600000 0x1000>;
			ranges = <0 0x08600000 0x1000>;

			#address-cells = <1>;
			#size-cells = <1>;

			tz-log-buf-addr@720 {
				compatible = "qcom,msm-imem-tz-log-buf-addr";
				reg = <0x720 4>;
			};

			restart-reason-buf-addr@7b0 {
				compatible = "qcom,msm-imem-restart-reason-buf-addr";
				reg = <0x7b0 4>;
			};

			restart-reason-buf-q6-addr@7b4 {
				compatible = "qcom,imem-restart-reason-buf-q6-addr";
				reg = <0x7b4 4>;
			};

			restart-reason-buf-wr-addr@7ac {
				compatible = "qcom,imem-restart-reason-buf-wr-addr";
				reg = <0x7ac 4>;
			};
		};

		qusb_phy_1: phy@71000 {
			compatible = "qcom,ipq5424-qusb2-phy";
			reg = <0x071000 0x180>;
			#phy-cells = <0>;

			clocks = <&gcc GCC_USB1_PHY_CFG_AHB_CLK>,
				<&xo>;
			clock-names = "cfg_ahb", "ref";

			resets = <&gcc GCC_QUSB2_1_PHY_BCR>;
			status = "disabled";
		};

		usb2: usb2@1e00000 {
			compatible = "qcom,ipq5424-dwc3", "qcom,dwc3";
			reg = <0x1ef8800 0x400>;
			#address-cells = <1>;
			#size-cells = <1>;
			ranges;

			clocks = <&gcc GCC_USB1_MASTER_CLK>,
				 <&gcc GCC_USB1_SLEEP_CLK>,
				 <&gcc GCC_USB1_MOCK_UTMI_CLK>,
				 <&gcc GCC_USB1_PHY_CFG_AHB_CLK>;

			clock-names = "master",
				      "sleep",
				      "mock_utmi",
				      "cfg_ahb_clk";

			assigned-clocks = <&gcc GCC_USB1_MASTER_CLK>,
					  <&gcc GCC_USB1_MOCK_UTMI_CLK>;
			assigned-clock-rates = <200000000>,
					       <24000000>;

			resets = <&gcc GCC_USB1_BCR>;
			qcom,select-utmi-as-pipe-clk;
			status = "disabled";

			dwc_1: dwc3@1e00000 {
				compatible = "snps,dwc3";
				reg = <0x1e00000 0xe000>;
				clocks = <&gcc GCC_USB1_MOCK_UTMI_CLK>;
				clock-names = "ref";
				interrupts = <GIC_SPI 396 IRQ_TYPE_LEVEL_HIGH>;
				phys = <&qusb_phy_1>;
				phy-names = "usb2-phy";
				tx-fifo-resize;
				snps,is-utmi-l1-suspend;
				snps,hird-threshold = /bits/ 8 <0x0>;
				snps,dis_u2_susphy_quirk;
				snps,dis_u3_susphy_quirk;
				maximum-speed = "high-speed";
				dr_mode = "host";
			};
		};

		qusb_phy_0: phy@7b000 {
			compatible = "qcom,ipq5424-qusb2-phy";
			reg = <0x07b000 0x180>;
			#phy-cells = <0>;

			clocks = <&gcc GCC_USB0_PHY_CFG_AHB_CLK>,
				<&xo>;
			clock-names = "cfg_ahb", "ref";

			resets = <&gcc GCC_QUSB2_0_PHY_BCR>;
			status = "disabled";
		};

		ssphy_0: phy@7d000 {
			compatible = "qcom,ipq5424-qmp-usb3-phy";
			reg = <0x0007d000 0xa00>;
			#phy-cells = <0>;

			clocks = <&gcc GCC_USB0_AUX_CLK>,
				 <&xo>,
				 <&gcc GCC_USB0_PHY_CFG_AHB_CLK>,
				 <&gcc GCC_USB0_PIPE_CLK>;
			clock-names = "aux",
				      "ref",
				      "cfg_ahb",
				      "pipe";

			resets = <&gcc GCC_USB0_PHY_BCR>,
				 <&gcc GCC_USB3PHY_0_PHY_BCR>;
			reset-names = "phy",
				      "phy_phy";

			#clock-cells = <0>;
			clock-output-names = "usb0_pipe_clk";

			status = "disabled";
		};

		usb3: usb3@8a00000 {
			compatible = "qcom,ipq5424-dwc3", "qcom,dwc3";
			reg = <0x8af8800 0x400>,
			      <0x8b80000 0x4000>;
			#address-cells = <1>;
			#size-cells = <1>;
			ranges;

			clocks = <&gcc GCC_USB0_MASTER_CLK>,
				<&gcc GCC_USB0_SLEEP_CLK>,
				<&gcc GCC_USB0_MOCK_UTMI_CLK>,
				<&gcc GCC_USB0_PHY_CFG_AHB_CLK>,
				<&gcc GCC_USB0_AUX_CLK>,
				<&gcc GCC_USB0_PIPE_CLK>,
				<&gcc GCC_CNOC_USB_CLK>;

			clock-names = "master",
				"sleep",
				"mock_utmi",
				"cfg_ahb_clk",
				"aux_clk",
				"pipe_clk",
				"cnoc_usb_clk";

			assigned-clocks = <&gcc GCC_USB0_MASTER_CLK>,
					  <&gcc GCC_USB0_MOCK_UTMI_CLK>;
			assigned-clock-rates = <200000000>,
					       <24000000>;

			resets = <&gcc GCC_USB_BCR>;
			status = "disabled";

			dwc_0: dwc3@8a00000 {
				compatible = "snps,dwc3";
				reg = <0x8a00000 0xcd00>;
				clocks = <&gcc GCC_USB0_MOCK_UTMI_CLK>;
				clock-names = "ref";
				interrupts = <GIC_SPI 409 IRQ_TYPE_LEVEL_HIGH>;
				phys = <&qusb_phy_0>, <&ssphy_0>;
				phy-names = "usb2-phy", "usb3-phy";
				tx-fifo-resize;
				snps,is-utmi-l1-suspend;
				snps,hird-threshold = /bits/ 8 <0x0>;
				snps,dis_u2_susphy_quirk;
				snps,dis_u3_susphy_quirk;
				dr_mode = "host";
			};
		};

		reg_update: reg-update@0 {
			compatible = "ipq,54xx-reg-update";
			reg = <0>;
			secure-reg = <0x00610808 0x80>, /* aggr_noc_pcie0 */
				     <0x00610908 0x80>, /* aggr_noc_pcie1 */
				     <0x00610a08 0x80>, /* aggr_noc_pcie2 */
				     <0x00610b08 0x80>; /* aggr_noc_pcie3 */
			status = "okay";
		};
	};

	timer {
		compatible = "arm,armv8-timer";
		interrupts = <GIC_PPI 13 (GIC_CPU_MASK_SIMPLE(4) | IRQ_TYPE_LEVEL_LOW)>,
			     <GIC_PPI 14 (GIC_CPU_MASK_SIMPLE(4) | IRQ_TYPE_LEVEL_LOW)>,
			     <GIC_PPI 11 (GIC_CPU_MASK_SIMPLE(4) | IRQ_TYPE_LEVEL_LOW)>,
			     <GIC_PPI 10 (GIC_CPU_MASK_SIMPLE(4) | IRQ_TYPE_LEVEL_LOW)>,
			     <GIC_PPI 12 (GIC_CPU_MASK_SIMPLE(4) | IRQ_TYPE_LEVEL_LOW)>;
	};

	tmel-log {
		compatible = "qcom,tmel-log-ipq5424";
	};

	qcom,test@0 {
		compatible = "qcom,testmhi";
		qcom,wlan-ramdump-dynamic = <0x600000>;
	};

	wcss: wcss-smp2p {
		compatible = "qcom,smp2p";
		qcom,smem = <435>, <428>;

		interrupt-parent = <&intc>;
		interrupts = <GIC_SPI 501 IRQ_TYPE_EDGE_RISING>;

		mboxes = <&apcs_glb 9>;

		qcom,local-pid = <0>;
		qcom,remote-pid = <1>;
		global_timer = <0x4A5000>;

		wcss_smp2p_out: master-kernel {
			qcom,entry-name = "master-kernel";
			#qcom,smem-state-cells = <1>;
		};

		wcss_smp2p_in: slave-kernel {
			qcom,entry-name = "slave-kernel";
			interrupt-controller;
			#interrupt-cells = <2>;
		};
	};

	ipq-debug {
		compatible = "qcom,ipq-debug-ipq5424";
		qcom,rproc = <&q6v5_wcss>;
	};

	thermal_zones: thermal-zones {
		cpu0-thermal {
			polling-delay-passive = <0>;
			polling-delay = <0>;
			thermal-sensors = <&tsens 14>;

			trips {
				cpu-critical {
					temperature = <120000>;
					hysteresis = <9000>;
					type = "critical";
				};

				cpu0_thermal_alert: cpu-passive {
					temperature = <110000>;
					hysteresis = <9000>;
					type = "passive";
				};
			};

			cooling-maps {
				map0 {
					trip = <&cpu0_thermal_alert>;
					/* Set maximum frequency as 816 MHz */
					cooling-device = <&CPU0 2 2>,
							 <&CPU1 2 2>,
							 <&CPU2 2 2>,
							 <&CPU3 2 2>;
				};
			};
		};

		cpu1-thermal {
			polling-delay-passive = <0>;
			polling-delay = <0>;
			thermal-sensors = <&tsens 12>;

			trips {
				cpu-critical {
					temperature = <120000>;
					hysteresis = <9000>;
					type = "critical";
				};

				cpu-passive {
					temperature = <110000>;
					hysteresis = <9000>;
					type = "passive";
				};
			};
		};

		cpu2-thermal {
			polling-delay-passive = <0>;
			polling-delay = <0>;
			thermal-sensors = <&tsens 11>;

			trips {
				cpu-critical {
					temperature = <120000>;
					hysteresis = <9000>;
					type = "critical";
				};

				cpu-passive {
					temperature = <110000>;
					hysteresis = <9000>;
					type = "passive";
				};
			};
		};

		cpu3-thermal {
			polling-delay-passive = <0>;
			polling-delay = <0>;
			thermal-sensors = <&tsens 13>;

			trips {
				cpu-critical {
					temperature = <120000>;
					hysteresis = <9000>;
					type = "critical";
				};

				cpu-passive {
					temperature = <110000>;
					hysteresis = <9000>;
					type = "passive";
				};
			};
		};

		wcss-tile2-thermal {
			polling-delay-passive = <0>;
			polling-delay = <0>;
			thermal-sensors = <&tsens 9>;

			trips {
				wcss_tile2-critical {
					temperature = <125000>;
					hysteresis = <9000>;
					type = "critical";
				};
			};
		};

		wcss-tile3-thermal {
			polling-delay-passive = <0>;
			polling-delay = <0>;
			thermal-sensors = <&tsens 10>;

			trips {
				wcss_tile3-critical {
					temperature = <125000>;
					hysteresis = <9000>;
					type = "critical";
				};
			};
		};

		top-glue-thermal {
			polling-delay-passive = <0>;
			polling-delay = <0>;
			thermal-sensors = <&tsens 15>;

			trips {
				top-glue-critical {
					temperature = <125000>;
					hysteresis = <9000>;
					type = "critical";
				};
			};
		};
	};
};

#ifndef __CPU_THERMAL__
#include "ipq5424-thermald.dtsi"
#endif
